VERSION ""

NS_ :

BS_:

BU_:

BO_ 256 M_Data: 8 BMS1
 SG_ Unique_ID : 16|48@1+ (1,0) [0|0] "ID"  BMS2,Cluster,TCU
 SG_ SoC : 0|16@1+ (0.1,0.0) [0.0|100.0] "%"  BMS2,Cluster,TCU

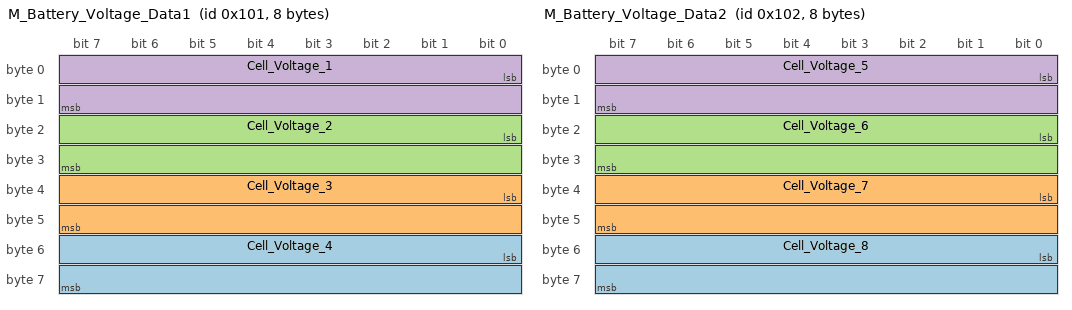
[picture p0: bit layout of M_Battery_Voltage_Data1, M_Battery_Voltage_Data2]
BO_ 257 M_Battery_Voltage_Data1: 8 BMS1
 SG_ Cell_Voltage_4 : 48|16@1+ (1,0) [0.0|5000.0] "mV"  TCU
 SG_ Cell_Voltage_3 : 32|16@1+ (1,0) [0.0|5000.0] "mV"  TCU
 SG_ Cell_Voltage_2 : 16|16@1+ (1,0) [0.0|5000.0] "mV"  TCU
 SG_ Cell_Voltage_1 : 0|16@1+ (1,0) [0.0|5000.0] "mV"  TCU

BO_ 258 M_Battery_Voltage_Data2: 8 BMS1
 SG_ Cell_Voltage_8 : 48|16@1+ (1,0) [0.0|5000.0] "mV"  TCU
 SG_ Cell_Voltage_7 : 32|16@1+ (1,0) [0.0|5000.0] "mV"  TCU
 SG_ Cell_Voltage_6 : 16|16@1+ (1,0) [0.0|5000.0] "mV"  TCU
 SG_ Cell_Voltage_5 : 0|16@1+ (1,0) [0.0|5000.0] "mV"  TCU

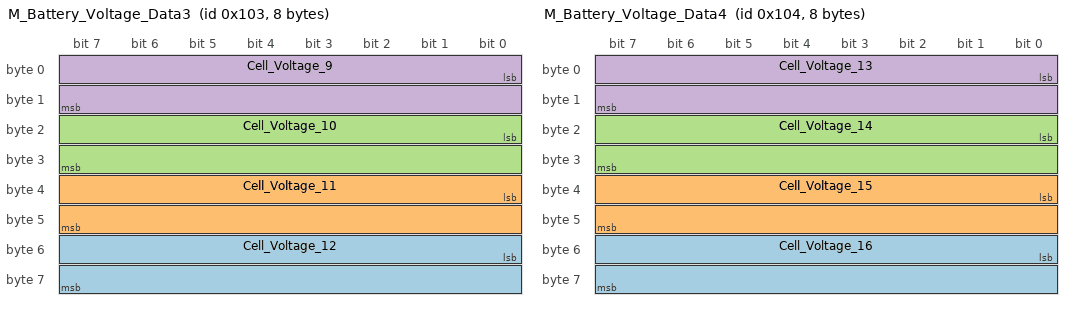
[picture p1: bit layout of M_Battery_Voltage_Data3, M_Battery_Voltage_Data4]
BO_ 259 M_Battery_Voltage_Data3: 8 BMS1
 SG_ Cell_Voltage_12 : 48|16@1+ (1,0) [0.0|5000.0] "mV"  TCU
 SG_ Cell_Voltage_11 : 32|16@1+ (1,0) [0.0|5000.0] "mV"  TCU
 SG_ Cell_Voltage_10 : 16|16@1+ (1,0) [0.0|5000.0] "mV"  TCU
 SG_ Cell_Voltage_9 : 0|16@1+ (1,0) [0.0|5000.0] "mV"  TCU

BO_ 260 M_Battery_Voltage_Data4: 8 BMS1
 SG_ Cell_Voltage_16 : 48|16@1+ (1,0) [0.0|5000.0] "mV"  TCU
 SG_ Cell_Voltage_15 : 32|16@1+ (1,0) [0.0|5000.0] "mV"  TCU
 SG_ Cell_Voltage_14 : 16|16@1+ (1,0) [0.0|5000.0] "mV"  TCU
 SG_ Cell_Voltage_13 : 0|16@1+ (1,0) [0.0|5000.0] "mV"  TCU

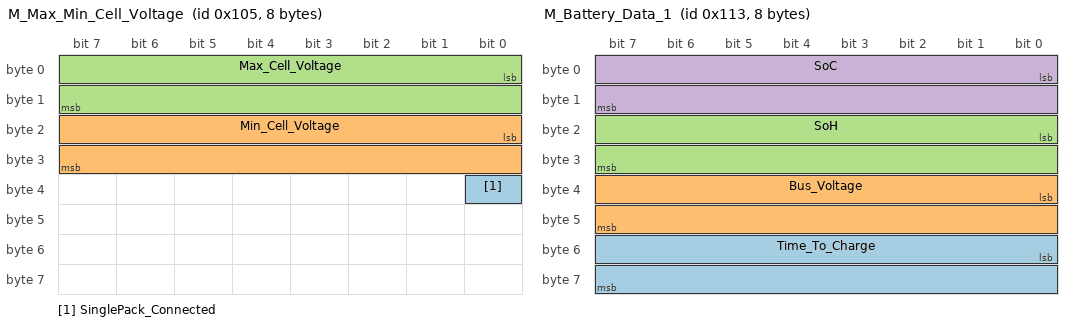
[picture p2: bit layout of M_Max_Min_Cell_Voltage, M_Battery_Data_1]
BO_ 261 M_Max_Min_Cell_Voltage: 8 BMS1
 SG_ SinglePack_Connected : 32|1@1+ (1,0) [0.0|1.0] ""  TCU
 SG_ Min_Cell_Voltage : 16|16@1+ (1,0) [0.0|5000.0] "mV"  TCU
 SG_ Max_Cell_Voltage : 0|16@1+ (1,0) [0.0|5000.0] "mV"  TCU

BO_ 262 M_Battery_PDU_Temp_Data: 8 BMS1
 SG_ PDU_Temperature_BMS : 16|16@1+ (0.01,-55.0) [-55.0|200.0] "degC"  TCU
 SG_ PDU_Temperature_AFE : 0|16@1+ (0.01,-55.0) [-55.0|200.0] "degC"  TCU

BO_ 263 M_Battery_Temp_Data_1: 8 BMS1
 SG_ Battery_Pack_Effective_Temp : 16|16@1+ (0.01,-55.0) [-55.0|200.0] "degC"  Cluster,OBC,TCU
 SG_ Balancing_Temperature_AFE : 0|16@1+ (0.01,-55.0) [-55.0|200.0] "degC"  Cluster,OBC,TCU

BO_ 264 M_Battery_Temp_Data_2: 8 BMS1
 SG_ Battery_Pack_Temp_Sensor_2 : 16|16@1+ (0.01,-55.0) [-55.0|200.0] "degC"  TCU
 SG_ Battery_Pack_Temp_Sensor_1 : 0|16@1+ (0.01,-55.0) [-55.0|200.0] "degC"  TCU

BO_ 265 M_Battery_Temp_Data_3: 8 BMS1
 SG_ Battery_Pack_Temp_Sensor_4 : 16|16@1+ (0.01,-55.0) [-55.0|200.0] "degC"  TCU
 SG_ Battery_Pack_Temp_Sensor_3 : 0|16@1+ (0.01,-55.0) [-55.0|200.0] "degC"  TCU

BO_ 272 M_BMS_Status_Data_1: 8 BMS1
 SG_ Cell16_Balancing_Status : 34|1@1+ (1,0) [0.0|1.0] ""  TCU
 SG_ Cell15_Balancing_Status : 33|1@1+ (1,0) [0.0|1.0] ""  TCU
 SG_ Cell14_Balancing_Status : 32|1@1+ (1,0) [0.0|1.0] ""  TCU
 SG_ Cell13_Balancing_Status : 31|1@1+ (1,0) [0.0|1.0] ""  TCU
 SG_ Cell12_Balancing_Status : 30|1@1+ (1,0) [0.0|1.0] ""  TCU
 SG_ Cell11_Balancing_Status : 29|1@1+ (1,0) [0.0|1.0] ""  TCU
 SG_ Cell10_Balancing_Status : 28|1@1+ (1,0) [0.0|1.0] ""  TCU
 SG_ Cell9_Balancing_Status : 27|1@1+ (1,0) [0.0|1.0] ""  TCU
 SG_ Cell8_Balancing_Status : 26|1@1+ (1,0) [0.0|1.0] ""  TCU
 SG_ Cell7_Balancing_Status : 25|1@1+ (1,0) [0.0|1.0] ""  TCU
 SG_ Cell6_Balancing_Status : 24|1@1+ (1,0) [0.0|1.0] ""  TCU
 SG_ Cell5_Balancing_Status : 23|1@1+ (1,0) [0.0|1.0] ""  TCU
 SG_ Cell4_Balancing_Status : 22|1@1+ (1,0) [0.0|1.0] ""  TCU
 SG_ Cell3_Balancing_Status : 21|1@1+ (1,0) [0.0|1.0] ""  TCU
 SG_ Cell2_Balancing_Status : 20|1@1+ (1,0) [0.0|1.0] ""  TCU
 SG_ Cell1_Balancing_Status : 19|1@1+ (1,0) [0.0|1.0] ""  TCU
 SG_ BMS_SlowChg_Status : 18|1@1+ (1,0) [0.0|1.0] ""  TCU
 SG_ BMS_SlowChg_Auth : 17|1@1+ (1,0) [0.0|1.0] ""  TCU
 SG_ BMS_Out_3_3VEnable : 16|1@1+ (1,0) [0.0|1.0] ""  TCU
 SG_ BMS_Out_Overload_Clear : 15|1@1+ (1,0) [0.0|1.0] ""  TCU
 SG_ BMS_Out_AFE_Reset : 14|1@1+ (1,0) [0.0|1.0] ""  TCU
 SG_ BMS_Out_Precharge_FET_Enable : 13|1@1+ (1,0) [0.0|1.0] ""  TCU
 SG_ BMS_Out_Discharge_FET_Enable : 12|1@1+ (1,0) [0.0|1.0] ""  TCU
 SG_ BMS_Out_Charge_FET_Enable : 11|1@1+ (1,0) [0.0|1.0] ""  TCU
 SG_ BMS_Out_Gate_Driver_Enable : 10|1@1+ (1,0) [0.0|1.0] ""  TCU
 SG_ BMS_Out_5VEnable : 9|1@1+ (1,0) [0.0|1.0] ""  TCU
 SG_ BMS_Out_9VEnable : 8|1@1+ (1,0) [0.0|1.0] ""  TCU
 SG_ BMS_Out_12VEnable : 7|1@1+ (1,0) [0.0|1.0] ""  TCU
 SG_ BMS_Out_Status : 6|1@1+ (1,0) [0.0|1.0] ""  TCU
 SG_ BMS_IN_PlugSense : 5|1@1+ (1,0) [0.0|1.0] ""  TCU
 SG_ BMS_IN_Discharge_Overcurrent : 4|1@1+ (1,0) [0.0|1.0] ""  TCU
 SG_ BMS_IN_Charge_Overcurrent : 3|1@1+ (1,0) [0.0|1.0] ""  TCU
 SG_ BMS_IN_AFE_Fault : 2|1@1+ (1,0) [0.0|1.0] ""  TCU
 SG_ BMS_IN_Supply_12V : 1|1@1+ (1,0) [0.0|1.0] ""  TCU
 SG_ BMS_IN_Supply_9V : 0|1@1+ (1,0) [0.0|1.0] ""  TCU

BO_ 273 M_Current_Limit_Data: 8 BMS1
 SG_ Regenerative_Current_Limit : 16|16@1+ (0.1,0.0) [0.0|100.0] "A"  MCU,TCU
 SG_ Discharge_Current_Limit : 0|16@1+ (0.1,-200.0) [-200.0|0.0] "A"  MCU,TCU

BO_ 274 M_Battery_Pack_V_I: 8 BMS1
 SG_ Battery_Pack_Voltage : 16|16@1+ (0.1,0.0) [0.0|100.0] "V"  MCU,TCU
 SG_ Battery_Pack_Current : 0|16@1+ (0.1,-200.0) [0.0|200.0] "A"  MCU,TCU

BO_ 275 M_Battery_Data_1: 8 BMS1
 SG_ Time_To_Charge : 48|16@1+ (1,0) [0|0] ""  Cluster,MCU,OBC,TCU
 SG_ Bus_Voltage : 32|16@1+ (0.1,0.0) [0.0|100.0] "V"  Cluster,MCU,OBC,TCU
 SG_ SoH : 16|16@1+ (0.1,0.0) [0.0|100.0] "%"  Cluster,MCU,OBC,TCU
 SG_ SoC : 0|16@1+ (0.1,0.0) [0.0|100.0] "%"  Cluster,MCU,OBC,TCU

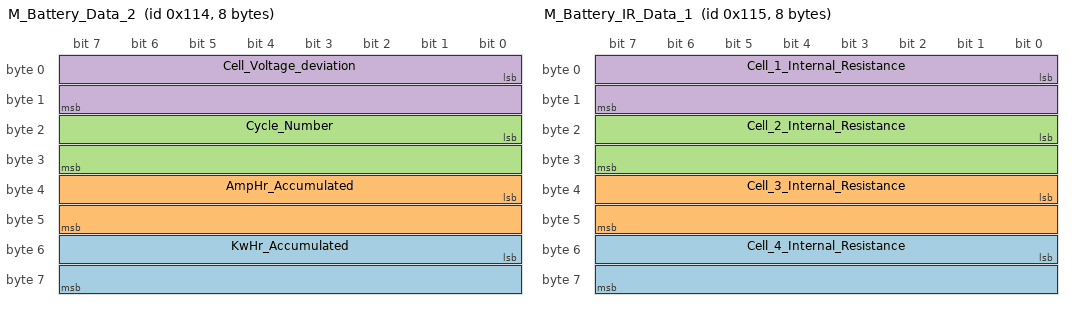
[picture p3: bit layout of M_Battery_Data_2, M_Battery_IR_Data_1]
BO_ 276 M_Battery_Data_2: 8 BMS1
 SG_ KwHr_Accumulated : 48|16@1+ (0.01,0.0) [0.0|6.0] "KwHr"  TCU
 SG_ AmpHr_Accumulated : 32|16@1+ (0.1,0.0) [0.0|100.0] "AmpHr"  TCU
 SG_ Cycle_Number : 16|16@1+ (1,0) [0.0|3000.0] "Count"  TCU
 SG_ Cell_Voltage_deviation : 0|16@1+ (1,0) [0.0|5000.0] "mV"  TCU

BO_ 277 M_Battery_IR_Data_1: 8 BMS1
 SG_ Cell_4_Internal_Resistance : 48|16@1+ (1,0) [0|0] "mOhm"  TCU
 SG_ Cell_3_Internal_Resistance : 32|16@1+ (1,0) [0|0] "mOhm"  TCU
 SG_ Cell_2_Internal_Resistance : 16|16@1+ (1,0) [0|0] "mOhm"  TCU
 SG_ Cell_1_Internal_Resistance : 0|16@1+ (1,0) [0|0] "mOhm"  TCU

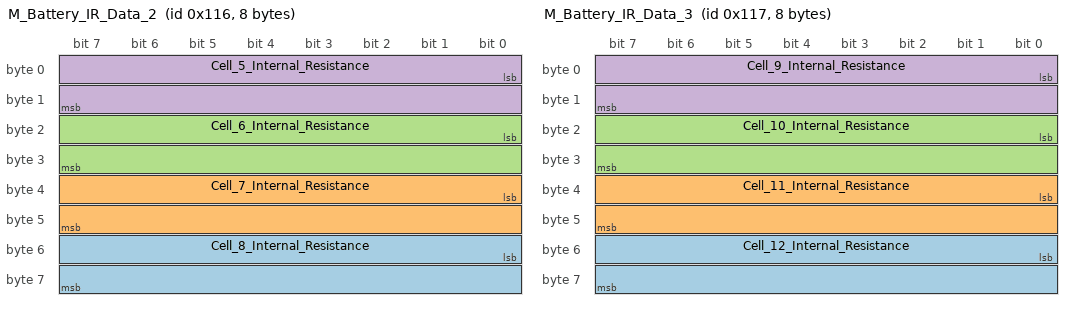
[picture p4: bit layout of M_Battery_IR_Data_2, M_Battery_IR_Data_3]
BO_ 278 M_Battery_IR_Data_2: 8 BMS1
 SG_ Cell_8_Internal_Resistance : 48|16@1+ (1,0) [0|0] "mOhm"  TCU
 SG_ Cell_7_Internal_Resistance : 32|16@1+ (1,0) [0|0] "mOhm"  TCU
 SG_ Cell_6_Internal_Resistance : 16|16@1+ (1,0) [0|0] "mOhm"  TCU
 SG_ Cell_5_Internal_Resistance : 0|16@1+ (1,0) [0|0] "mOhm"  TCU

BO_ 279 M_Battery_IR_Data_3: 8 BMS1
 SG_ Cell_12_Internal_Resistance : 48|16@1+ (1,0) [0|0] "mOhm"  TCU
 SG_ Cell_11_Internal_Resistance : 32|16@1+ (1,0) [0|0] "mOhm"  TCU
 SG_ Cell_10_Internal_Resistance : 16|16@1+ (1,0) [0|0] "mOhm"  TCU
 SG_ Cell_9_Internal_Resistance : 0|16@1+ (1,0) [0|0] "mOhm"  TCU

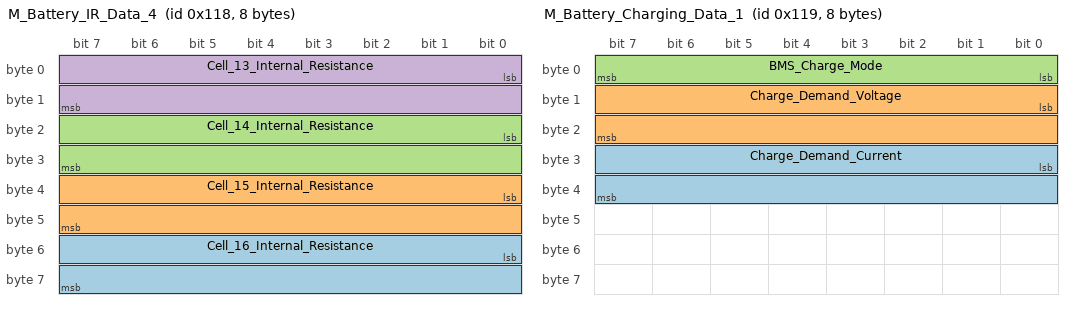
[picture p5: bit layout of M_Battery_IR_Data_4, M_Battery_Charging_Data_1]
BO_ 280 M_Battery_IR_Data_4: 8 BMS1
 SG_ Cell_16_Internal_Resistance : 48|16@1+ (1,0) [0|0] "mOhm"  TCU
 SG_ Cell_15_Internal_Resistance : 32|16@1+ (1,0) [0|0] "mOhm"  TCU
 SG_ Cell_14_Internal_Resistance : 16|16@1+ (1,0) [0|0] "mOhm"  TCU
 SG_ Cell_13_Internal_Resistance : 0|16@1+ (1,0) [0|0] "mOhm"  TCU

BO_ 281 M_Battery_Charging_Data_1: 8 BMS1
 SG_ Charge_Demand_Current : 24|16@1+ (0.1,0.0) [0|0] "mA"  OBC,TCU
 SG_ Charge_Demand_Voltage : 8|16@1+ (0.1,0.0) [0.0|100.0] "V"  OBC,TCU
 SG_ BMS_Charge_Mode : 0|8@1+ (1,0) [0.0|5.0] ""  OBC,TCU

BO_ 288 M_Battery_Data_3: 8 BMS1
 SG_ RTC_Date : 0|48@1+ (1,0) [0|0] "Sec"  TCU

BO_ 289 M_Battery_Data_4: 8 BMS1
 SG_ RTC_Time : 0|48@1+ (1,0) [0|0] ""  TCU

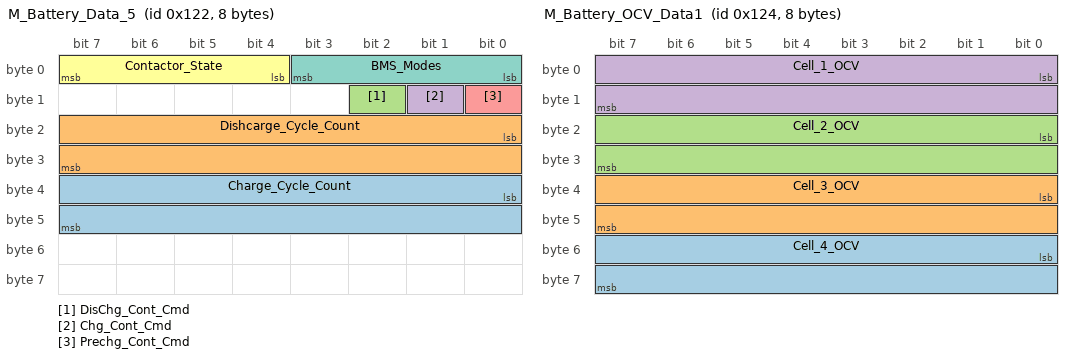
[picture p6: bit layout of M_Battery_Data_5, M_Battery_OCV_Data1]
BO_ 290 M_Battery_Data_5: 8 BMS1
 SG_ Charge_Cycle_Count : 32|16@1+ (1,0) [0.0|1000.0] "Count"  BMS2,MCU,TCU
 SG_ Dishcarge_Cycle_Count : 16|16@1+ (1,0) [0.0|1000.0] "Count"  BMS2,MCU,TCU
 SG_ DisChg_Cont_Cmd : 10|1@1+ (1,0) [0.0|1.0] ""  BMS2,MCU,TCU
 SG_ Chg_Cont_Cmd : 9|1@1+ (1,0) [0.0|1.0] ""  BMS2,MCU,TCU
 SG_ Prechg_Cont_Cmd : 8|1@1+ (1,0) [0.0|1.0] ""  BMS2,MCU,TCU
 SG_ Contactor_State : 4|4@1+ (1,0) [0.0|5.0] ""  BMS2,MCU,TCU
 SG_ BMS_Modes : 0|4@1+ (1,0) [0.0|7.0] ""  BMS2,MCU,TCU

BO_ 291 M_Battery_Fault_Data: 8 BMS1
 SG_ Ther_RunAway_Alert : 26|1@1+ (1,0) [0.0|1.0] ""  TCU
 SG_ Therm_RunAway_CutOFF : 25|1@1+ (1,0) [0.0|1.0] ""  TCU
 SG_ PDU_TempRise_Perm : 24|1@1+ (1,0) [0.0|1.0] ""  TCU
 SG_ Batt_TempRise_Perm : 23|1@1+ (1,0) [0.0|1.0] ""  TCU
 SG_ Dis_CutOff : 22|1@1+ (1,0) [0.0|1.0] ""  TCU
 SG_ Charge_CutOff : 21|1@1+ (1,0) [0.0|1.0] ""  TCU
 SG_ Dis_OvrTemp_Err : 20|1@1+ (1,0) [0.0|1.0] ""  TCU
 SG_ Dis_OvrTemp_Warn : 19|1@1+ (1,0) [0.0|1.0] ""  TCU
 SG_ Chg_OvrTemp_Warn : 18|1@1+ (1,0) [0.0|1.0] ""  TCU
 SG_ Chg_Und_Vol_Warn : 17|1@1+ (1,0) [0.0|1.0] ""  TCU
 SG_ Chg_Ovr_Vol_Perm : 16|1@1+ (1,0) [0.0|1.0] ""  TCU
 SG_ Chg_Ovr_Vol_Err : 15|1@1+ (1,0) [0.0|1.0] ""  TCU
 SG_ Chg_Ovr_Vol_Warn : 14|1@1+ (1,0) [0.0|1.0] ""  TCU
 SG_ PDU_Temp_Err : 13|1@1+ (1,0) [0.0|1.0] ""  TCU
 SG_ Over_Temp_Perm : 12|1@1+ (1,0) [0.0|1.0] ""  TCU
 SG_ Short_Circuit_Perm : 11|1@1+ (1,0) [0.0|1.0] ""  TCU
 SG_ Short_Circuit_Err : 10|1@1+ (1,0) [0.0|1.0] ""  TCU
 SG_ Cell_Und_Voltage_Perm : 9|1@1+ (1,0) [0.0|1.0] ""  TCU
 SG_ Cell_Ovr_Voltage_Perm : 8|1@1+ (1,0) [0.0|1.0] ""  TCU
 SG_ Cell_Und_Voltage_Err : 7|1@1+ (1,0) [0.0|1.0] ""  TCU
 SG_ Cell_Ovr_Voltage_Err : 6|1@1+ (1,0) [0.0|1.0] ""  TCU
 SG_ Dis_Connection_Err : 5|1@1+ (1,0) [0.0|1.0] ""  TCU
 SG_ Main_Connection_Err : 4|1@1+ (1,0) [0.0|1.0] ""  TCU
 SG_ Precharge_Fail_Perm : 3|1@1+ (1,0) [0.0|1.0] ""  TCU
 SG_ Precharge_Fail : 2|1@1+ (1,0) [0.0|1.0] ""  TCU
 SG_ PreCharge_Err_Short : 1|1@1+ (1,0) [0.0|1.0] ""  TCU
 SG_ BMS_CutOff : 0|1@1+ (1,0) [0.0|1.0] ""  TCU

BO_ 292 M_Battery_OCV_Data1: 8 BMS1
 SG_ Cell_4_OCV : 48|16@1+ (1,0) [0.0|5000.0] "mV"  TCU
 SG_ Cell_3_OCV : 32|16@1+ (1,0) [0.0|5000.0] "mV"  TCU
 SG_ Cell_2_OCV : 16|16@1+ (1,0) [0.0|5000.0] "mV"  TCU
 SG_ Cell_1_OCV : 0|16@1+ (1,0) [0.0|5000.0] "mV"  TCU

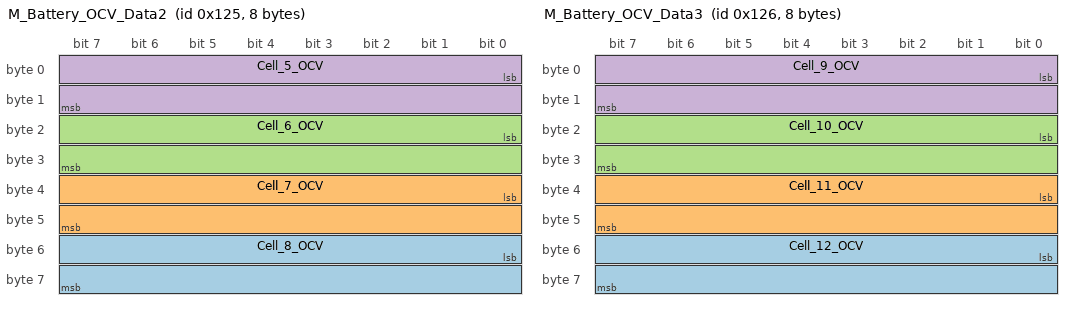
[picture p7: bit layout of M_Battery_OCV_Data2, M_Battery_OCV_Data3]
BO_ 293 M_Battery_OCV_Data2: 8 BMS1
 SG_ Cell_8_OCV : 48|16@1+ (1,0) [0.0|5000.0] "mV"  TCU
 SG_ Cell_7_OCV : 32|16@1+ (1,0) [0.0|5000.0] "mV"  TCU
 SG_ Cell_6_OCV : 16|16@1+ (1,0) [0.0|5000.0] "mV"  TCU
 SG_ Cell_5_OCV : 0|16@1+ (1,0) [0.0|5000.0] "mV"  TCU

BO_ 294 M_Battery_OCV_Data3: 8 BMS1
 SG_ Cell_12_OCV : 48|16@1+ (1,0) [0.0|5000.0] "mV"  TCU
 SG_ Cell_11_OCV : 32|16@1+ (1,0) [0.0|5000.0] "mV"  TCU
 SG_ Cell_10_OCV : 16|16@1+ (1,0) [0.0|5000.0] "mV"  TCU
 SG_ Cell_9_OCV : 0|16@1+ (1,0) [0.0|5000.0] "mV"  TCU

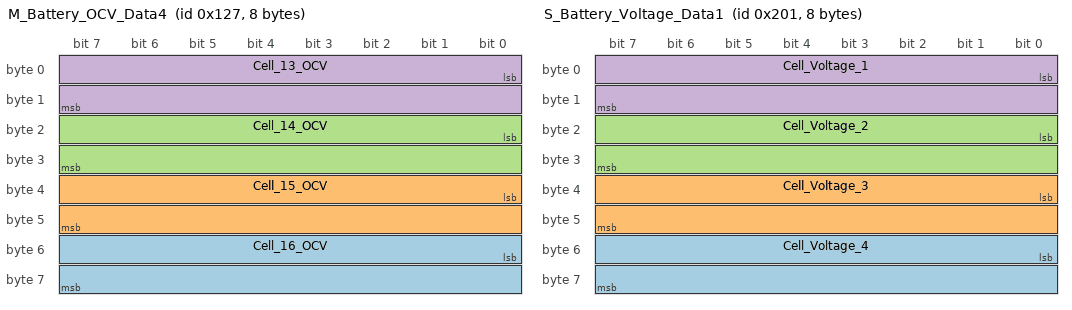
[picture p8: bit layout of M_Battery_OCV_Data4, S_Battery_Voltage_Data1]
BO_ 295 M_Battery_OCV_Data4: 8 BMS1
 SG_ Cell_16_OCV : 48|16@1+ (1,0) [0.0|5000.0] "mV"  TCU
 SG_ Cell_15_OCV : 32|16@1+ (1,0) [0.0|5000.0] "mV"  TCU
 SG_ Cell_14_OCV : 16|16@1+ (1,0) [0.0|5000.0] "mV"  TCU
 SG_ Cell_13_OCV : 0|16@1+ (1,0) [0.0|5000.0] "mV"  TCU

BO_ 512 S_Data: 8 BMS2
 SG_ Unique_ID : 16|48@1+ (1,0) [0|0] "ID"  BMS1,Cluster,TCU
 SG_ SoC : 0|16@1+ (0.1,0.0) [0.0|100.0] "%"  BMS1,Cluster,TCU

BO_ 513 S_Battery_Voltage_Data1: 8 BMS2
 SG_ Cell_Voltage_4 : 48|16@1+ (1,0) [0.0|5000.0] "mV"  TCU
 SG_ Cell_Voltage_3 : 32|16@1+ (1,0) [0.0|5000.0] "mV"  TCU
 SG_ Cell_Voltage_2 : 16|16@1+ (1,0) [0.0|5000.0] "mV"  TCU
 SG_ Cell_Voltage_1 : 0|16@1+ (1,0) [0.0|5000.0] "mV"  TCU

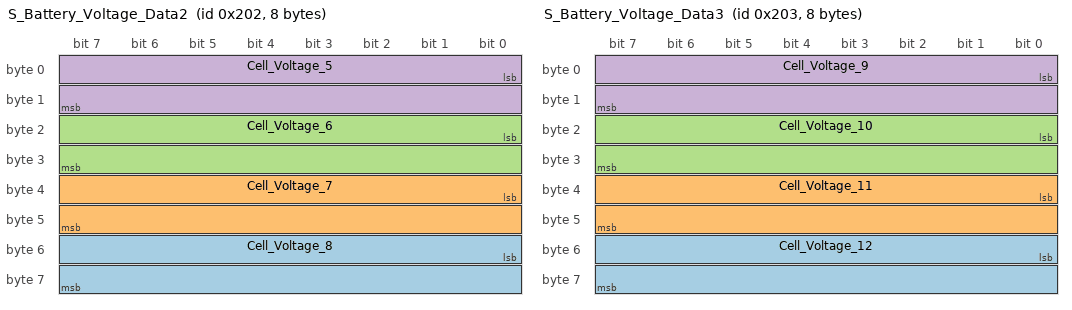
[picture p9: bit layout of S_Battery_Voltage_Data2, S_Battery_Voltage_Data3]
BO_ 514 S_Battery_Voltage_Data2: 8 BMS2
 SG_ Cell_Voltage_8 : 48|16@1+ (1,0) [0.0|5000.0] "mV"  TCU
 SG_ Cell_Voltage_7 : 32|16@1+ (1,0) [0.0|5000.0] "mV"  TCU
 SG_ Cell_Voltage_6 : 16|16@1+ (1,0) [0.0|5000.0] "mV"  TCU
 SG_ Cell_Voltage_5 : 0|16@1+ (1,0) [0.0|5000.0] "mV"  TCU

BO_ 515 S_Battery_Voltage_Data3: 8 BMS2
 SG_ Cell_Voltage_12 : 48|16@1+ (1,0) [0.0|5000.0] "mV"  TCU
 SG_ Cell_Voltage_11 : 32|16@1+ (1,0) [0.0|5000.0] "mV"  TCU
 SG_ Cell_Voltage_10 : 16|16@1+ (1,0) [0.0|5000.0] "mV"  TCU
 SG_ Cell_Voltage_9 : 0|16@1+ (1,0) [0.0|5000.0] "mV"  TCU

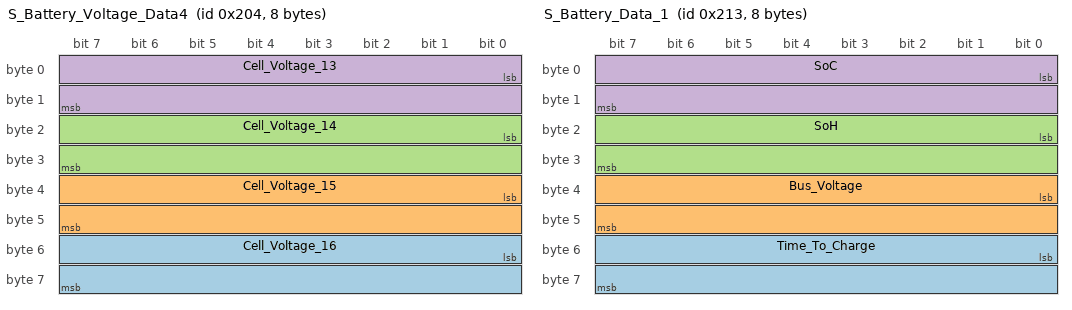
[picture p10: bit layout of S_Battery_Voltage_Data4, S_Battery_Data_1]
BO_ 516 S_Battery_Voltage_Data4: 8 BMS2
 SG_ Cell_Voltage_16 : 48|16@1+ (1,0) [0.0|5000.0] "mV"  TCU
 SG_ Cell_Voltage_15 : 32|16@1+ (1,0) [0.0|5000.0] "mV"  TCU
 SG_ Cell_Voltage_14 : 16|16@1+ (1,0) [0.0|5000.0] "mV"  TCU
 SG_ Cell_Voltage_13 : 0|16@1+ (1,0) [0.0|5000.0] "mV"  TCU

BO_ 517 S_Max_Min_Cell_Voltage: 8 BMS2
 SG_ Min_Cell_Voltage : 16|16@1+ (1,0) [0.0|5000.0] "mV"  TCU
 SG_ Max_Cell_Voltage : 0|16@1+ (1,0) [0.0|5000.0] "mV"  TCU

BO_ 518 S_Battery_PDU_Temp_Data: 8 BMS2
 SG_ PDU_Temperature_BMS : 16|16@1+ (0.01,-55.0) [-55.0|200.0] "degC"  OBC,TCU
 SG_ PDU_Temperature_AFE : 0|16@1+ (0.01,-55.0) [-55.0|200.0] "degC"  OBC,TCU

BO_ 519 S_Battery_Temp_Data_1: 8 BMS2
 SG_ Battery_Pack_Effective_Temp : 16|16@1+ (0.01,-55.0) [-55.0|200.0] "degC"  OBC,TCU
 SG_ Balancing_Temperature_AFE : 0|16@1+ (0.01,-55.0) [-55.0|200.0] "degC"  OBC,TCU

BO_ 520 S_Battery_Temp_Data_2: 8 BMS2
 SG_ Battery_Pack_Temp_Sensor_2 : 16|16@1+ (0.01,-55.0) [-55.0|200.0] "degC"  OBC,TCU
 SG_ Battery_Pack_Temp_Sensor_1 : 0|16@1+ (0.01,-55.0) [-55.0|200.0] "degC"  OBC,TCU

BO_ 521 S_Battery_Temp_Data_3: 8 BMS2
 SG_ Battery_Pack_Temp_Sensor_4 : 16|16@1+ (0.01,-55.0) [-55.0|200.0] "degC"  OBC,TCU
 SG_ Battery_Pack_Temp_Sensor_3 : 0|16@1+ (0.01,-55.0) [-55.0|200.0] "degC"  OBC,TCU

BO_ 528 S_BMS_Status_Data_1: 8 BMS2
 SG_ Cell16_Balancing_Status : 34|1@1+ (1,0) [0.0|1.0] ""  TCU
 SG_ Cell15_Balancing_Status : 33|1@1+ (1,0) [0.0|1.0] ""  TCU
 SG_ Cell14_Balancing_Status : 32|1@1+ (1,0) [0.0|1.0] ""  TCU
 SG_ Cell13_Balancing_Status : 31|1@1+ (1,0) [0.0|1.0] ""  TCU
 SG_ Cell12_Balancing_Status : 30|1@1+ (1,0) [0.0|1.0] ""  TCU
 SG_ Cell11_Balancing_Status : 29|1@1+ (1,0) [0.0|1.0] ""  TCU
 SG_ Cell10_Balancing_Status : 28|1@1+ (1,0) [0.0|1.0] ""  TCU
 SG_ Cell9_Balancing_Status : 27|1@1+ (1,0) [0.0|1.0] ""  TCU
 SG_ Cell8_Balancing_Status : 26|1@1+ (1,0) [0.0|1.0] ""  TCU
 SG_ Cell7_Balancing_Status : 25|1@1+ (1,0) [0.0|1.0] ""  TCU
 SG_ Cell6_Balancing_Status : 24|1@1+ (1,0) [0.0|1.0] ""  TCU
 SG_ Cell5_Balancing_Status : 23|1@1+ (1,0) [0.0|1.0] ""  TCU
 SG_ Cell4_Balancing_Status : 22|1@1+ (1,0) [0.0|1.0] ""  TCU
 SG_ Cell3_Balancing_Status : 21|1@1+ (1,0) [0.0|1.0] ""  TCU
 SG_ Cell2_Balancing_Status : 20|1@1+ (1,0) [0.0|1.0] ""  TCU
 SG_ Cell1_Balancing_Status : 19|1@1+ (1,0) [0.0|1.0] ""  TCU
 SG_ BMS_SlowChg_Status : 18|1@1+ (1,0) [0.0|1.0] ""  TCU
 SG_ BMS_SlowChg_Auth : 17|1@1+ (1,0) [0.0|1.0] ""  TCU
 SG_ BMS_Out_3_3VEnable : 16|1@1+ (1,0) [0.0|1.0] ""  TCU
 SG_ BMS_Out_Overload_Clear : 15|1@1+ (1,0) [0.0|1.0] ""  TCU
 SG_ BMS_Out_AFE_Reset : 14|1@1+ (1,0) [0.0|1.0] ""  TCU
 SG_ BMS_Out_Precharge_FET_Enable : 13|1@1+ (1,0) [0.0|1.0] ""  TCU
 SG_ BMS_Out_Discharge_FET_Enable : 12|1@1+ (1,0) [0.0|1.0] ""  TCU
 SG_ BMS_Out_Charge_FET_Enable : 11|1@1+ (1,0) [0.0|1.0] ""  TCU
 SG_ BMS_Out_Gate_Driver_Enable : 10|1@1+ (1,0) [0.0|1.0] ""  TCU
 SG_ BMS_Out_5VEnable : 9|1@1+ (1,0) [0.0|1.0] ""  TCU
 SG_ BMS_Out_9VEnable : 8|1@1+ (1,0) [0.0|1.0] ""  TCU
 SG_ BMS_Out_12VEnable : 7|1@1+ (1,0) [0.0|1.0] ""  TCU
 SG_ BMS_Out_Status : 6|1@1+ (1,0) [0.0|1.0] ""  TCU
 SG_ BMS_IN_PlugSense : 5|1@1+ (1,0) [0.0|1.0] ""  TCU
 SG_ BMS_IN_Discharge_Overcurrent : 4|1@1+ (1,0) [0.0|1.0] ""  TCU
 SG_ BMS_IN_Charge_Overcurrent : 3|1@1+ (1,0) [0.0|1.0] ""  TCU
 SG_ BMS_IN_AFE_Fault : 2|1@1+ (1,0) [0.0|1.0] ""  TCU
 SG_ BMS_IN_Supply_12V : 1|1@1+ (1,0) [0.0|1.0] ""  TCU
 SG_ BMS_IN_Supply_9V : 0|1@1+ (1,0) [0.0|1.0] ""  TCU

BO_ 529 S_Current_Limit_Data: 8 BMS2
 SG_ Regenerative_Current_Limit : 16|16@1+ (1,0) [-200.0|600.0] "A"  MCU,TCU
 SG_ Discharge_Current_Limit : 0|16@1+ (1,0) [-200.0|200.0] "A"  MCU,TCU

BO_ 530 S_Battery_Pack_V_I: 8 BMS2
 SG_ Battery_Pack_Voltage : 16|16@1+ (0.1,0.0) [0.0|100.0] "V"  MCU,TCU
 SG_ Battery_Pack_Current : 0|16@1+ (0.1,0.0) [0.0|200.0] "A"  MCU,TCU

BO_ 531 S_Battery_Data_1: 8 BMS2
 SG_ Time_To_Charge : 48|16@1+ (1,0) [0|0] ""  MCU,OBC,TCU
 SG_ Bus_Voltage : 32|16@1+ (0.1,0.0) [0.0|100.0] "V"  MCU,OBC,TCU
 SG_ SoH : 16|16@1+ (0.1,0.0) [0.0|100.0] "%"  MCU,OBC,TCU
 SG_ SoC : 0|16@1+ (0.1,0.0) [0.0|100.0] "%"  MCU,OBC,TCU

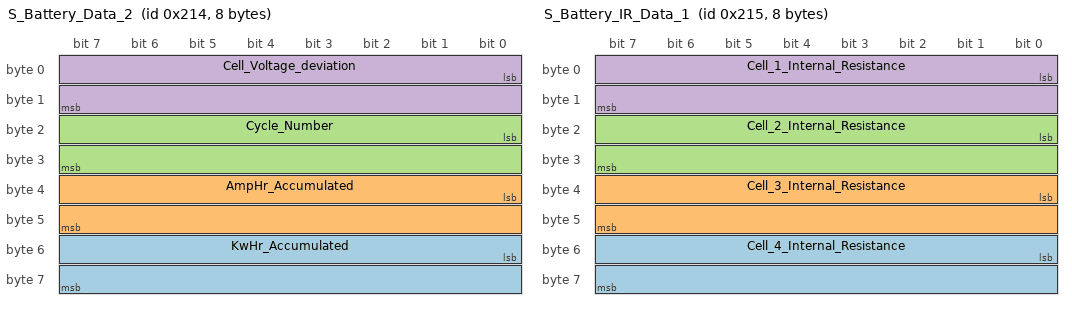
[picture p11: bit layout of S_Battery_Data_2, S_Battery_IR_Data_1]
BO_ 532 S_Battery_Data_2: 8 BMS2
 SG_ KwHr_Accumulated : 48|16@1+ (0.01,0.0) [0.0|6.0] "KwHr"  TCU
 SG_ AmpHr_Accumulated : 32|16@1+ (0.1,0.0) [0.0|100.0] "AmpHr"  TCU
 SG_ Cycle_Number : 16|16@1+ (1,0) [0.0|3000.0] "Count"  TCU
 SG_ Cell_Voltage_deviation : 0|16@1+ (1,0) [0.0|5000.0] "mV"  TCU

BO_ 533 S_Battery_IR_Data_1: 8 BMS2
 SG_ Cell_4_Internal_Resistance : 48|16@1+ (1,0) [0|0] "mOhm"  TCU
 SG_ Cell_3_Internal_Resistance : 32|16@1+ (1,0) [0|0] "mOhm"  TCU
 SG_ Cell_2_Internal_Resistance : 16|16@1+ (1,0) [0|0] "mOhm"  TCU
 SG_ Cell_1_Internal_Resistance : 0|16@1+ (1,0) [0|0] "mOhm"  TCU

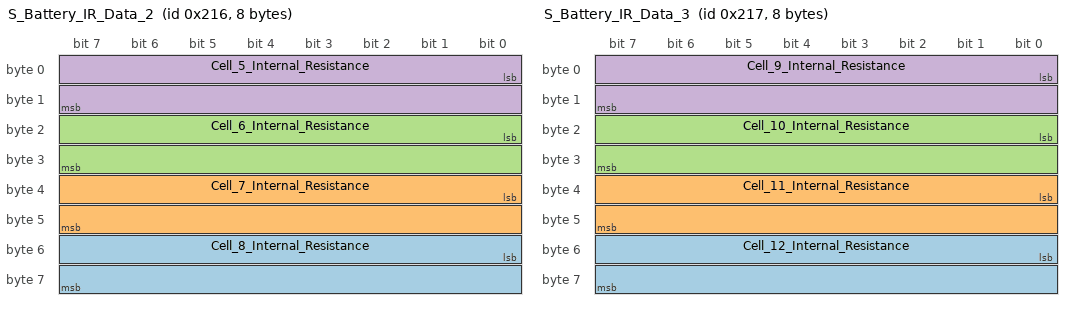
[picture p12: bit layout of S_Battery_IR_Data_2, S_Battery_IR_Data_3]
BO_ 534 S_Battery_IR_Data_2: 8 BMS2
 SG_ Cell_8_Internal_Resistance : 48|16@1+ (1,0) [0|0] "mOhm"  TCU
 SG_ Cell_7_Internal_Resistance : 32|16@1+ (1,0) [0|0] "mOhm"  TCU
 SG_ Cell_6_Internal_Resistance : 16|16@1+ (1,0) [0|0] "mOhm"  TCU
 SG_ Cell_5_Internal_Resistance : 0|16@1+ (1,0) [0|0] "mOhm"  TCU

BO_ 535 S_Battery_IR_Data_3: 8 BMS2
 SG_ Cell_12_Internal_Resistance : 48|16@1+ (1,0) [0|0] "mOhm"  TCU
 SG_ Cell_11_Internal_Resistance : 32|16@1+ (1,0) [0|0] "mOhm"  TCU
 SG_ Cell_10_Internal_Resistance : 16|16@1+ (1,0) [0|0] "mOhm"  TCU
 SG_ Cell_9_Internal_Resistance : 0|16@1+ (1,0) [0|0] "mOhm"  TCU

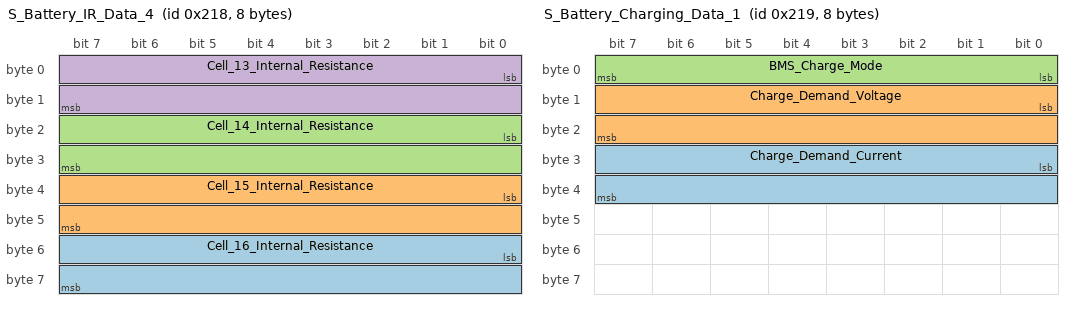
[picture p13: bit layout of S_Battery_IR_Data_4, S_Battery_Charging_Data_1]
BO_ 536 S_Battery_IR_Data_4: 8 BMS2
 SG_ Cell_16_Internal_Resistance : 48|16@1+ (1,0) [0|0] "mOhm"  TCU
 SG_ Cell_15_Internal_Resistance : 32|16@1+ (1,0) [0|0] "mOhm"  TCU
 SG_ Cell_14_Internal_Resistance : 16|16@1+ (1,0) [0|0] "mOhm"  TCU
 SG_ Cell_13_Internal_Resistance : 0|16@1+ (1,0) [0|0] "mOhm"  TCU

BO_ 537 S_Battery_Charging_Data_1: 8 BMS2
 SG_ Charge_Demand_Current : 24|16@1+ (0.1,0.0) [0|0] "mA"  OBC,TCU
 SG_ Charge_Demand_Voltage : 8|16@1+ (0.1,0.0) [0.0|100.0] "V"  OBC,TCU
 SG_ BMS_Charge_Mode : 0|8@1+ (1,0) [0.0|5.0] ""  OBC,TCU

BO_ 544 S_Battery_Data_3: 8 BMS2
 SG_ RTC_Date : 0|48@1+ (1,0) [0|0] "Sec"  TCU

BO_ 545 S_Battery_Data_4: 8 BMS2
 SG_ RTC_Time : 0|48@1+ (1,0) [0|0] ""  TCU

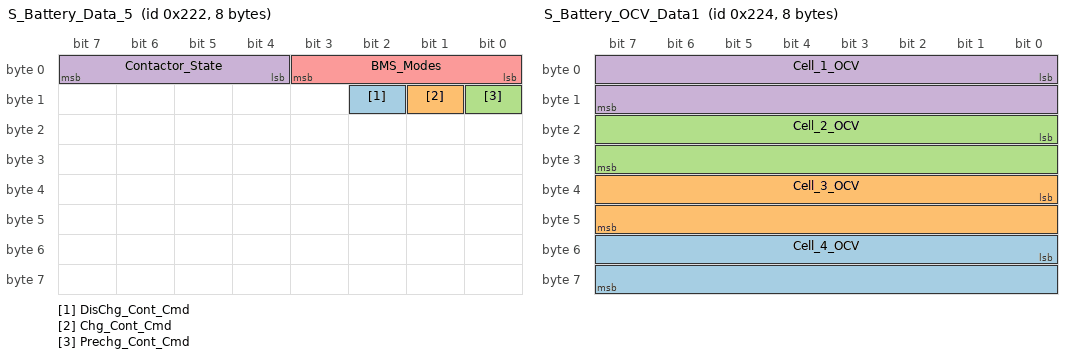
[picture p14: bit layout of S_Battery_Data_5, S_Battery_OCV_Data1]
BO_ 546 S_Battery_Data_5: 8 BMS2
 SG_ DisChg_Cont_Cmd : 10|1@1+ (1,0) [0.0|1.0] ""  BMS1,MCU,TCU
 SG_ Chg_Cont_Cmd : 9|1@1+ (1,0) [0.0|1.0] ""  BMS1,MCU,TCU
 SG_ Prechg_Cont_Cmd : 8|1@1+ (1,0) [0.0|1.0] ""  BMS1,MCU,TCU
 SG_ Contactor_State : 4|4@1+ (1,0) [0.0|5.0] ""  BMS1,MCU,TCU
 SG_ BMS_Modes : 0|4@1+ (1,0) [0.0|7.0] ""  BMS1,MCU,TCU

BO_ 547 S_Battery_Fault_Data: 8 BMS2
 SG_ Ther_RunAway_Alert : 26|1@1+ (1,0) [0.0|1.0] ""  TCU
 SG_ Therm_RunAway_CutOFF : 25|1@1+ (1,0) [0.0|1.0] ""  TCU
 SG_ PDU_TempRise_Perm : 24|1@1+ (1,0) [0.0|1.0] ""  TCU
 SG_ Batt_TempRise_Perm : 23|1@1+ (1,0) [0.0|1.0] ""  TCU
 SG_ Dis_CutOff : 22|1@1+ (1,0) [0.0|1.0] ""  TCU
 SG_ Charge_CutOff : 21|1@1+ (1,0) [0.0|1.0] ""  TCU
 SG_ Dis_OvrTemp_Err : 20|1@1+ (1,0) [0.0|1.0] ""  TCU
 SG_ Dis_OvrTemp_Warn : 19|1@1+ (1,0) [0.0|1.0] ""  TCU
 SG_ Chg_OvrTemp_Warn : 18|1@1+ (1,0) [0.0|1.0] ""  TCU
 SG_ Chg_Und_Vol_Warn : 17|1@1+ (1,0) [0.0|1.0] ""  TCU
 SG_ Chg_Ovr_Vol_Perm : 16|1@1+ (1,0) [0.0|1.0] ""  TCU
 SG_ Chg_Ovr_Vol_Err : 15|1@1+ (1,0) [0.0|1.0] ""  TCU
 SG_ Chg_Ovr_Vol_Warn : 14|1@1+ (1,0) [0.0|1.0] ""  TCU
 SG_ PDU_Temp_Err : 13|1@1+ (1,0) [0.0|1.0] ""  TCU
 SG_ Over_Temp_Perm : 12|1@1+ (1,0) [0.0|1.0] ""  TCU
 SG_ Short_Circuit_Perm : 11|1@1+ (1,0) [0.0|1.0] ""  TCU
 SG_ Short_Circuit_Err : 10|1@1+ (1,0) [0.0|1.0] ""  TCU
 SG_ Cell_Und_Voltage_Perm : 9|1@1+ (1,0) [0.0|1.0] ""  TCU
 SG_ Cell_Ovr_Voltage_Perm : 8|1@1+ (1,0) [0.0|1.0] ""  TCU
 SG_ Cell_Und_Voltage : 7|1@1+ (1,0) [0.0|1.0] ""  TCU
 SG_ Cell_Ovr_Voltage : 6|1@1+ (1,0) [0.0|1.0] ""  TCU
 SG_ Dis_Connection_Err : 5|1@1+ (1,0) [0.0|1.0] ""  TCU
 SG_ Main_Connection_Err : 4|1@1+ (1,0) [0.0|1.0] ""  TCU
 SG_ Precharge_Fail_Perm : 3|1@1+ (1,0) [0.0|1.0] ""  TCU
 SG_ Precharge_Fail : 2|1@1+ (1,0) [0.0|1.0] ""  TCU
 SG_ PreCharge_Err_Short : 1|1@1+ (1,0) [0.0|1.0] ""  TCU
 SG_ BMS_CutOff : 0|1@1+ (1,0) [0.0|1.0] ""  TCU

BO_ 548 S_Battery_OCV_Data1: 8 BMS2
 SG_ Cell_4_OCV : 48|16@1+ (1,0) [0.0|5000.0] "mV"  TCU
 SG_ Cell_3_OCV : 32|16@1+ (1,0) [0.0|5000.0] "mV"  TCU
 SG_ Cell_2_OCV : 16|16@1+ (1,0) [0.0|5000.0] "mV"  TCU
 SG_ Cell_1_OCV : 0|16@1+ (1,0) [0.0|5000.0] "mV"  TCU

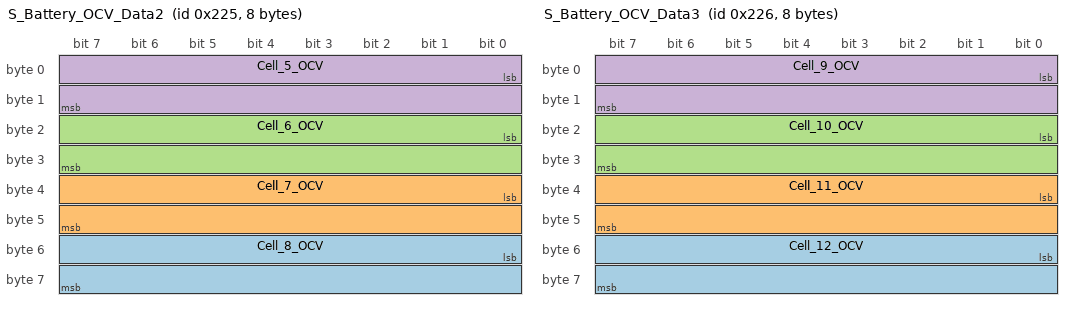
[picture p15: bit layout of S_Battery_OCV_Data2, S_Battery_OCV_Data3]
BO_ 549 S_Battery_OCV_Data2: 8 BMS2
 SG_ Cell_8_OCV : 48|16@1+ (1,0) [0.0|5000.0] "mV"  TCU
 SG_ Cell_7_OCV : 32|16@1+ (1,0) [0.0|5000.0] "mV"  TCU
 SG_ Cell_6_OCV : 16|16@1+ (1,0) [0.0|5000.0] "mV"  TCU
 SG_ Cell_5_OCV : 0|16@1+ (1,0) [0.0|5000.0] "mV"  TCU

BO_ 550 S_Battery_OCV_Data3: 8 BMS2
 SG_ Cell_12_OCV : 48|16@1+ (1,0) [0.0|5000.0] "mV"  TCU
 SG_ Cell_11_OCV : 32|16@1+ (1,0) [0.0|5000.0] "mV"  TCU
 SG_ Cell_10_OCV : 16|16@1+ (1,0) [0.0|5000.0] "mV"  TCU
 SG_ Cell_9_OCV : 0|16@1+ (1,0) [0.0|5000.0] "mV"  TCU

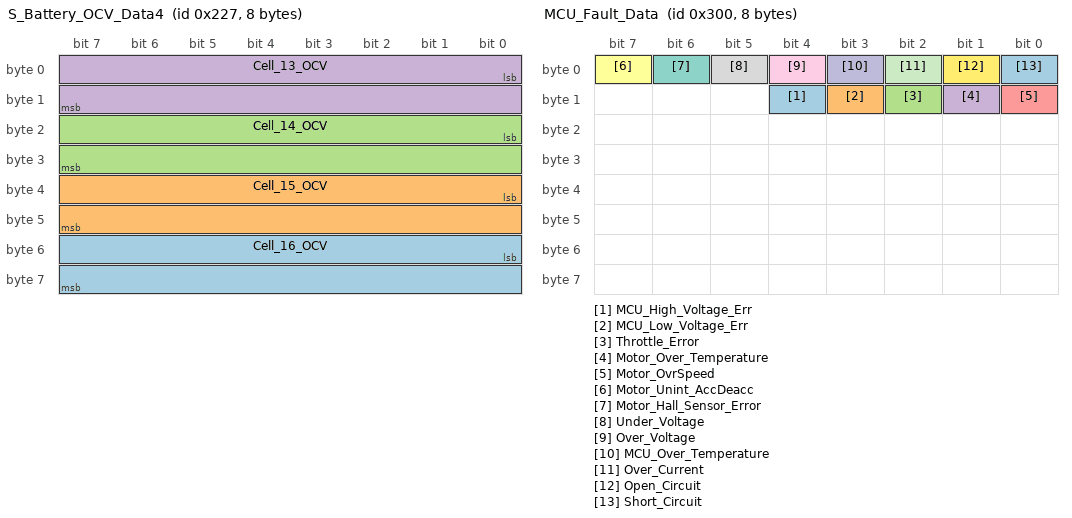
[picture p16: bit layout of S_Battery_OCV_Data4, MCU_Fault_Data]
BO_ 551 S_Battery_OCV_Data4: 8 BMS2
 SG_ Cell_16_OCV : 48|16@1+ (1,0) [0.0|5000.0] "mV"  TCU
 SG_ Cell_15_OCV : 32|16@1+ (1,0) [0.0|5000.0] "mV"  TCU
 SG_ Cell_14_OCV : 16|16@1+ (1,0) [0.0|5000.0] "mV"  TCU
 SG_ Cell_13_OCV : 0|16@1+ (1,0) [0.0|5000.0] "mV"  TCU

BO_ 768 MCU_Fault_Data: 8 MCU
 SG_ MCU_High_Voltage_Err : 12|1@1+ (1,0) [0.0|1.0] ""  BMS1,BMS2,Cluster,TCU
 SG_ MCU_Low_Voltage_Err : 11|1@1+ (1,0) [0.0|1.0] ""  BMS1,BMS2,Cluster,TCU
 SG_ Throttle_Error : 10|1@1+ (1,0) [0.0|1.0] ""  BMS1,BMS2,Cluster,TCU
 SG_ Motor_Over_Temperature : 9|1@1+ (1,0) [0.0|1.0] ""  BMS1,BMS2,Cluster,TCU
 SG_ Motor_OvrSpeed : 8|1@1+ (1,0) [0.0|1.0] ""  BMS1,BMS2,Cluster,TCU
 SG_ Motor_Unint_AccDeacc : 7|1@1+ (1,0) [0.0|1.0] ""  BMS1,BMS2,Cluster,TCU
 SG_ Motor_Hall_Sensor_Error : 6|1@1+ (1,0) [0.0|1.0] ""  BMS1,BMS2,Cluster,TCU
 SG_ Under_Voltage : 5|1@1+ (1,0) [0.0|1.0] ""  BMS1,BMS2,Cluster,TCU
 SG_ Over_Voltage : 4|1@1+ (1,0) [0.0|1.0] ""  BMS1,BMS2,Cluster,TCU
 SG_ MCU_Over_Temperature : 3|1@1+ (1,0) [0.0|1.0] ""  BMS1,BMS2,Cluster,TCU
 SG_ Over_Current : 2|1@1+ (1,0) [0.0|1.0] ""  BMS1,BMS2,Cluster,TCU
 SG_ Open_Circuit : 1|1@1+ (1,0) [0.0|1.0] ""  BMS1,BMS2,Cluster,TCU
 SG_ Short_Circuit : 0|1@1+ (1,0) [0.0|1.0] ""  BMS1,BMS2,Cluster,TCU

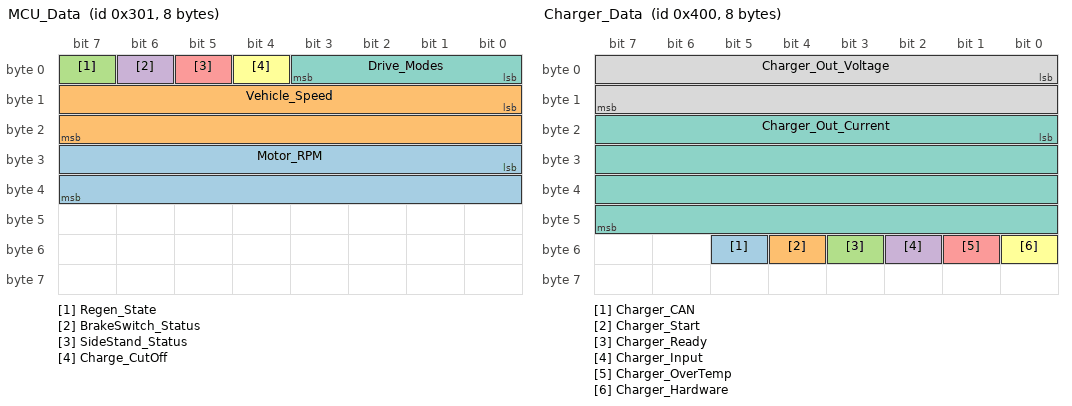
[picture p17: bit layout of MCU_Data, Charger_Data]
BO_ 769 MCU_Data: 8 MCU
 SG_ Motor_RPM : 24|16@1+ (1,0) [0.0|4000.0] "RPM"  BMS1,BMS2,Cluster,TCU
 SG_ Vehicle_Speed : 8|16@1+ (1,0) [0.0|200.0] "km/h"  BMS1,BMS2,Cluster,TCU
 SG_ Regen_State : 7|1@1+ (1,0) [0.0|1.0] ""  BMS1,BMS2,Cluster,TCU
 SG_ BrakeSwitch_Status : 6|1@1+ (1,0) [0.0|1.0] ""  BMS1,BMS2,Cluster,TCU
 SG_ SideStand_Status : 5|1@1+ (1,0) [0.0|1.0] ""  BMS1,BMS2,Cluster,TCU
 SG_ Charge_CutOff : 4|1@1+ (1,0) [0.0|1.0] ""  BMS1,BMS2,Cluster,TCU
 SG_ Drive_Modes : 0|4@1+ (1,0) [0.0|5.0] ""  BMS1,BMS2,Cluster,TCU

BO_ 770 MCU_Odo_Data: 8 MCU
 SG_ Trip_Odo_Data : 32|32@1+ (0.1,0.0) [0.0|4925672.0] "Meters"  Cluster,TCU
 SG_ Vehicle_Odo_Data : 0|32@1+ (0.1,0.0) [0.0|4925672.0] "Meters"  Cluster,TCU

BO_ 771 MCU_Temp_Data: 8 MCU
 SG_ Motor_Temp_Data : 16|16@1- (0.1,0.0) [0.0|4925672.0] "degC"  Cluster,TCU
 SG_ Controller_Temp_Data : 0|16@1- (0.1,0.0) [0.0|4925672.0] "degC"  Cluster,TCU

BO_ 1024 Charger_Data: 8 OBC
 SG_ Charger_CAN : 53|1@1+ (1,0) [0.0|1.0] ""  BMS1,BMS2,TCU
 SG_ Charger_Start : 52|1@1+ (1,0) [0.0|1.0] ""  BMS1,BMS2,TCU
 SG_ Charger_Ready : 51|1@1+ (1,0) [0.0|1.0] ""  BMS1,BMS2,TCU
 SG_ Charger_Input : 50|1@1+ (1,0) [0.0|1.0] ""  BMS1,BMS2,TCU
 SG_ Charger_OverTemp : 49|1@1+ (1,0) [0.0|1.0] ""  BMS1,BMS2,TCU
 SG_ Charger_Hardware : 48|1@1+ (1,0) [0.0|1.0] ""  BMS1,BMS2,TCU
 SG_ Charger_Out_Current : 16|32@1+ (0.1,0.0) [0.0|20.0] "A"  BMS1,BMS2,TCU
 SG_ Charger_Out_Voltage : 0|16@1+ (0.1,0.0) [0.0|60.0] "V"  BMS1,BMS2,TCU

BO_ 1408 Send_VCU_Cmd: 8 Vector__XXX
 SG_ Sim_Charger_Volt_Req : 48|10@1+ (0.1,0.0) [0.0|1.0] "" Vector__XXX
 SG_ Sim_BMS_Char_Curr_Req : 40|8@1+ (0.1,0.0) [0.0|1.0] "" Vector__XXX
 SG_ Discharge_Mode : 38|1@1+ (1,0) [0.0|1.0] "" Vector__XXX
 SG_ Direct_Enable : 37|1@1+ (1,0) [0.0|1.0] "" Vector__XXX
 SG_ Ovr_Temp_Enable : 36|1@1+ (1,0) [0.0|1.0] "" Vector__XXX
 SG_ Und_Temp_Enable : 35|1@1+ (1,0) [0.0|1.0] "" Vector__XXX
 SG_ Temp_Fault_Enable : 34|1@1+ (1,0) [0.0|1.0] "" Vector__XXX
 SG_ Sim_Charger_Current_Req_Flg : 33|1@1+ (1,0) [0.0|1.0] "" Vector__XXX
 SG_ Voltage_Fault_Enable : 32|1@1+ (1,0) [0.0|1.0] "" Vector__XXX
 SG_ Current_Sim_Value : 16|16@1+ (0.01,0.0) [0|0] "A" Vector__XXX
 SG_ Cell_Fault_OV : 15|1@1+ (1,0) [0.0|1.0] "" Vector__XXX
 SG_ Slm_Charger_Volt_Enable_Flag : 14|1@1+ (1,0) [0.0|1.0] "" Vector__XXX
 SG_ Cell_Fault_UV : 13|1@1+ (1,0) [0.0|1.0] "" Vector__XXX
 SG_ Simulation_Enable : 12|1@1+ (1,0) [0.0|1.0] "" Vector__XXX
 SG_ Current_Dir : 11|1@1+ (1,0) [0.0|1.0] "" Vector__XXX
 SG_ Vehicle_Mode_L3 : 9|2@1+ (1,0) [0.0|3.0] "" Vector__XXX
 SG_ Ign : 8|1@1+ (1,0) [0.0|1.0] "" Vector__XXX
 SG_ Vehicle_Mode_L2 : 6|2@1+ (1,0) [0.0|3.0] "" Vector__XXX
 SG_ BMS_WakUp_Req : 4|2@1+ (1,0) [0.0|1.0] "" Vector__XXX
 SG_ Diagnostic_Flg : 3|1@1+ (1,0) [0.0|1.0] "" Vector__XXX
 SG_ Charge_Connected : 2|1@1+ (1,0) [0.0|1.0] "" Vector__XXX
 SG_ VCU_Wakup_Req : 0|2@1+ (1,0) [0.0|2.0] "" Vector__XXX

CM_ SG_ 256 Unique_ID "Unique ID of the Master Battey pack";
CM_ SG_ 256 SoC "SoC of the Master battery pack";
CM_ SG_ 257 Cell_Voltage_4 "individual cell voltage";
CM_ SG_ 257 Cell_Voltage_3 "individual cell voltage";
CM_ SG_ 257 Cell_Voltage_2 "individual cell voltage";
CM_ SG_ 257 Cell_Voltage_1 "individual cell voltage";
CM_ SG_ 258 Cell_Voltage_8 "individual cell voltage";
CM_ SG_ 258 Cell_Voltage_7 "individual cell voltage";
CM_ SG_ 258 Cell_Voltage_6 "individual cell voltage";
CM_ SG_ 258 Cell_Voltage_5 "individual cell voltage";
CM_ SG_ 259 Cell_Voltage_12 "individual cell voltage";
CM_ SG_ 259 Cell_Voltage_11 "individual cell voltage";
CM_ SG_ 259 Cell_Voltage_10 "individual cell voltage";
CM_ SG_ 259 Cell_Voltage_9 "individual cell voltage";
CM_ SG_ 260 Cell_Voltage_16 "individual cell voltage";
CM_ SG_ 260 Cell_Voltage_15 "individual cell voltage";
CM_ SG_ 260 Cell_Voltage_14 "individual cell voltage";
CM_ SG_ 260 Cell_Voltage_13 "individual cell voltage";
CM_ SG_ 261 SinglePack_Connected "It will indicate how many packs connected in the vehcile";
CM_ SG_ 261 Min_Cell_Voltage "Minimum Voltage in 16 cells";
CM_ SG_ 261 Max_Cell_Voltage "Maximum voltage in 16 cells";
CM_ SG_ 262 PDU_Temperature_BMS "Temperature measured near the MOSFETs read by BMS";
CM_ SG_ 262 PDU_Temperature_AFE "PDU temperature read by AFE";
CM_ SG_ 263 Battery_Pack_Effective_Temp "Battery pack effective temperature (Tbatt)";
CM_ SG_ 263 Balancing_Temperature_AFE "Balancing temperature read by AFE";
CM_ SG_ 264 Battery_Pack_Temp_Sensor_2 "Measured Pack temperature from Sensor 2";
CM_ SG_ 264 Battery_Pack_Temp_Sensor_1 "Measured Pack temperature from Sensor 1";
CM_ SG_ 265 Battery_Pack_Temp_Sensor_4 "Measured Pack temperature from Sensor 4";
CM_ SG_ 265 Battery_Pack_Temp_Sensor_3 "Measured Pack temperature from Sensor 3";
CM_ SG_ 272 Cell16_Balancing_Status "1 for Cell balancing happening
0 for Cell balancing not happening";
CM_ SG_ 272 Cell15_Balancing_Status "1 for Cell balancing happening
0 for Cell balancing not happening";
CM_ SG_ 272 Cell14_Balancing_Status "1 for Cell balancing happening
0 for Cell balancing not happening";
CM_ SG_ 272 Cell13_Balancing_Status "1 for Cell balancing happening
0 for Cell balancing not happening";
CM_ SG_ 272 Cell12_Balancing_Status "1 for Cell balancing happening
0 for Cell balancing not happening";
CM_ SG_ 272 Cell11_Balancing_Status "1 for Cell balancing happening
0 for Cell balancing not happening";
CM_ SG_ 272 Cell10_Balancing_Status "1 for Cell balancing happening
0 for Cell balancing not happening";
CM_ SG_ 272 Cell9_Balancing_Status "1 for Cell balancing happening
0 for Cell balancing not happening";
CM_ SG_ 272 Cell8_Balancing_Status "1 for Cell balancing happening
0 for Cell balancing not happening";
CM_ SG_ 272 Cell7_Balancing_Status "1 for Cell balancing happening
0 for Cell balancing not happening";
CM_ SG_ 272 Cell6_Balancing_Status "1 for Cell balancing happening
0 for Cell balancing not happening";
CM_ SG_ 272 Cell5_Balancing_Status "1 for Cell balancing happening
0 for Cell balancing not happening";
CM_ SG_ 272 Cell4_Balancing_Status "1 for Cell balancing happening
0 for Cell balancing not happening";
CM_ SG_ 272 Cell3_Balancing_Status "1 for Cell balancing happening
0 for Cell balancing not happening";
CM_ SG_ 272 Cell2_Balancing_Status "1 for Cell balancing happening
0 for Cell balancing not happening";
CM_ SG_ 272 Cell1_Balancing_Status "1 for Cell balancing happening
0 for Cell balancing not happening";
CM_ SG_ 272 BMS_SlowChg_Status "If Attempt happens, Need to check whether it is Passed or Failed
0 for Failed
1 for Passed";
CM_ SG_ 272 BMS_SlowChg_Auth "BMS to Slow charge authentication";
CM_ SG_ 272 BMS_Out_Status "All BMS digital output status (ON or OFF) 0--> Off, 1--> On";
CM_ SG_ 272 BMS_IN_Supply_9V "All BMS digital input status (ON or OFF) 0--> Off, 1--> On";
CM_ SG_ 273 Regenerative_Current_Limit "Max amount of Current that Feedback in the battery which is generated by Regenerative Breaking System";
CM_ SG_ 273 Discharge_Current_Limit "Level of Charge Of Battery Relative to its Capacity";
CM_ SG_ 274 Battery_Pack_Voltage "Voltage of the Battery Pack";
CM_ SG_ 275 Time_To_Charge "Prediction time to complete 100% charge";
CM_ SG_ 275 Bus_Voltage "Measured voltage after MOSFETs (Bus voltage)";
CM_ SG_ 275 SoH "State of health (Indication of health of the pack)";
CM_ SG_ 275 SoC "State of charge (Indication of available energy in the pack)";
CM_ SG_ 276 KwHr_Accumulated "Accumalated energy of a cycle";
CM_ SG_ 276 AmpHr_Accumulated "Accumalated capacity of a cycle";
CM_ SG_ 276 Cycle_Number "Number of times pack is completely charged and discharged";
CM_ SG_ 276 Cell_Voltage_deviation "Difference between maximum and minimum cell voltages";
CM_ SG_ 277 Cell_4_Internal_Resistance "Calculated IR of cell 4";
CM_ SG_ 277 Cell_3_Internal_Resistance "Calculated IR of cell 3";
CM_ SG_ 277 Cell_2_Internal_Resistance "Calculated IR of cell 2";
CM_ SG_ 277 Cell_1_Internal_Resistance "Calculated IR of cell 1";
CM_ SG_ 278 Cell_8_Internal_Resistance "Calculated IR of cell 8";
CM_ SG_ 278 Cell_7_Internal_Resistance "Calculated IR of cell 7";
CM_ SG_ 278 Cell_6_Internal_Resistance "Calculated IR of cell 6";
CM_ SG_ 278 Cell_5_Internal_Resistance "Calculated IR of cell 5";
CM_ SG_ 279 Cell_12_Internal_Resistance "Calculated IR of cell 12";
CM_ SG_ 279 Cell_11_Internal_Resistance "Calculated IR of cell 11";
CM_ SG_ 279 Cell_10_Internal_Resistance "Calculated IR of cell 10";
CM_ SG_ 279 Cell_9_Internal_Resistance "Calculated IR of cell 9";
CM_ SG_ 280 Cell_16_Internal_Resistance "Calculated IR of cell 16";
CM_ SG_ 280 Cell_15_Internal_Resistance "Calculated IR of cell 15";
CM_ SG_ 280 Cell_14_Internal_Resistance "Calculated IR of cell 14";
CM_ SG_ 280 Cell_13_Internal_Resistance "Calculated IR of cell 13";
CM_ SG_ 281 Charge_Demand_Current "Only during charging";
CM_ SG_ 281 Charge_Demand_Voltage "Only during charging";
CM_ SG_ 281 BMS_Charge_Mode "Charging mode state";
CM_ SG_ 288 RTC_Date "Day, Month, Year";
CM_ SG_ 289 RTC_Time "RTC time (Hour, min, sec)";
CM_ SG_ 290 Contactor_State "Contactor States";
CM_ SG_ 290 BMS_Modes "BMS modes";
CM_ SG_ 291 Ther_RunAway_Alert "1 for Indication of Thermal Run Away Alert";
CM_ SG_ 291 Therm_RunAway_CutOFF "1 for Indication of Thermal Run Away CutOff";
CM_ SG_ 291 PDU_TempRise_Perm "1 for Indication of Permanent Temperature Rise In PDU";
CM_ SG_ 291 Batt_TempRise_Perm "1 for Indication of Permanent Temperature Rise in Battery";
CM_ SG_ 291 Dis_CutOff "1 for Indication of Discharge Cut Off";
CM_ SG_ 291 Charge_CutOff "1 for Indication of Charge Cut Off";
CM_ SG_ 291 Dis_OvrTemp_Err "1 for Indication of Discharge Over Temperature Error";
CM_ SG_ 291 Dis_OvrTemp_Warn "1 for Indication of Discharge Over Temperature Warning";
CM_ SG_ 291 Chg_OvrTemp_Warn "1 for Indication of Charge Over Temperature Warning";
CM_ SG_ 291 Chg_Und_Vol_Warn "1 for Indication of Charge Under Voltage Warning";
CM_ SG_ 291 Chg_Ovr_Vol_Perm "1 for Indication of Permanent Charge Over Voltage";
CM_ SG_ 291 Chg_Ovr_Vol_Err "1 for Indication of Charge Over Voltage Error";
CM_ SG_ 291 Chg_Ovr_Vol_Warn "1 for Indication of Charge Over Voltage Warning";
CM_ SG_ 291 PDU_Temp_Err "1 for Indication of PDU Temperature Error";
CM_ SG_ 291 Over_Temp_Perm "1 for Indication of Permanent Over Temperature";
CM_ SG_ 291 Short_Circuit_Perm "1 for Indication of Permanent Short Circuit";
CM_ SG_ 291 Short_Circuit_Err "1 for Indication of Short Circuit Error";
CM_ SG_ 291 Cell_Und_Voltage_Err "1 for Indication of Cell Under Voltage";
CM_ SG_ 291 Cell_Ovr_Voltage_Err "1 for Indication of Cell Over Voltage";
CM_ SG_ 291 Dis_Connection_Err "1 for Indication of DisConnection Error";
CM_ SG_ 291 Main_Connection_Err "1 for Indication of Main Connection Error";
CM_ SG_ 291 Precharge_Fail_Perm "1 for Indication of Precharge Fail Permanent";
CM_ SG_ 291 Precharge_Fail "1 for Indication of Precharge Fail";
CM_ SG_ 291 PreCharge_Err_Short "1 for Indication of Precharge Short";
CM_ SG_ 291 BMS_CutOff "1 for Indicaiton of BMS Cut Off mode";
CM_ SG_ 292 Cell_4_OCV "Estimated from measured cell voltage - cell4";
CM_ SG_ 292 Cell_3_OCV "Estimated from measured cell voltage - cell3";
CM_ SG_ 292 Cell_2_OCV "Estimated from measured cell voltage - cell2";
CM_ SG_ 292 Cell_1_OCV "Estimated from measured cell voltage - cell1";
CM_ SG_ 293 Cell_8_OCV "Estimated from measured cell voltage - cell8";
CM_ SG_ 293 Cell_7_OCV "Estimated from measured cell voltage - cell7";
CM_ SG_ 293 Cell_6_OCV "Estimated from measured cell voltage - cell6";
CM_ SG_ 293 Cell_5_OCV "Estimated from measured cell voltage - cell5";
CM_ SG_ 294 Cell_12_OCV "Estimated from measured cell voltage - cell12";
CM_ SG_ 294 Cell_11_OCV "Estimated from measured cell voltage - cell11";
CM_ SG_ 294 Cell_10_OCV "Estimated from measured cell voltage - cell10";
CM_ SG_ 294 Cell_9_OCV "Estimated from measured cell voltage - cell9";
CM_ SG_ 295 Cell_16_OCV "Estimated from measured cell voltage - cell16";
CM_ SG_ 295 Cell_15_OCV "Estimated from measured cell voltage - cell15";
CM_ SG_ 295 Cell_14_OCV "Estimated from measured cell voltage - cell14";
CM_ SG_ 295 Cell_13_OCV "Estimated from measured cell voltage - cell13";
CM_ SG_ 512 Unique_ID "Unique ID of the Master Battey pack";
CM_ SG_ 512 SoC "SoC of the Master battery pack";
CM_ SG_ 513 Cell_Voltage_4 "individual cell voltage";
CM_ SG_ 513 Cell_Voltage_3 "individual cell voltage";
CM_ SG_ 513 Cell_Voltage_2 "individual cell voltage";
CM_ SG_ 513 Cell_Voltage_1 "individual cell voltage";
CM_ SG_ 514 Cell_Voltage_8 "individual cell voltage";
CM_ SG_ 514 Cell_Voltage_7 "individual cell voltage";
CM_ SG_ 514 Cell_Voltage_6 "individual cell voltage";
CM_ SG_ 514 Cell_Voltage_5 "individual cell voltage";
CM_ SG_ 515 Cell_Voltage_12 "individual cell voltage";
CM_ SG_ 515 Cell_Voltage_11 "individual cell voltage";
CM_ SG_ 515 Cell_Voltage_10 "individual cell voltage";
CM_ SG_ 515 Cell_Voltage_9 "individual cell voltage";
CM_ SG_ 516 Cell_Voltage_16 "individual cell voltage";
CM_ SG_ 516 Cell_Voltage_15 "individual cell voltage";
CM_ SG_ 516 Cell_Voltage_14 "individual cell voltage";
CM_ SG_ 516 Cell_Voltage_13 "individual cell voltage";
CM_ SG_ 517 Min_Cell_Voltage "Minimum Voltage in 14 cells";
CM_ SG_ 517 Max_Cell_Voltage "Maximum voltage in 14 cells";
CM_ SG_ 518 PDU_Temperature_BMS "Temperature measured near the MOSFETs read by BMS";
CM_ SG_ 518 PDU_Temperature_AFE "PDU temperature read by AFE";
CM_ SG_ 519 Battery_Pack_Effective_Temp "Battery pack effective temperature (Tbatt)";
CM_ SG_ 519 Balancing_Temperature_AFE "Balancing temperature read by AFE";
CM_ SG_ 520 Battery_Pack_Temp_Sensor_2 "Measured Pack temperature from Sensor 2";
CM_ SG_ 520 Battery_Pack_Temp_Sensor_1 "Measured Pack temperature from Sensor 1";
CM_ SG_ 521 Battery_Pack_Temp_Sensor_4 "Measured Pack temperature from Sensor 4";
CM_ SG_ 521 Battery_Pack_Temp_Sensor_3 "Measured Pack temperature from Sensor 3";
CM_ SG_ 528 Cell16_Balancing_Status "1 for Cell balancing happening
0 for Cell balancing not happening";
CM_ SG_ 528 Cell15_Balancing_Status "1 for Cell balancing happening
0 for Cell balancing not happening";
CM_ SG_ 528 Cell14_Balancing_Status "1 for Cell balancing happening
0 for Cell balancing not happening";
CM_ SG_ 528 Cell13_Balancing_Status "1 for Cell balancing happening
0 for Cell balancing not happening";
CM_ SG_ 528 Cell12_Balancing_Status "1 for Cell balancing happening
0 for Cell balancing not happening";
CM_ SG_ 528 Cell11_Balancing_Status "1 for Cell balancing happening
0 for Cell balancing not happening";
CM_ SG_ 528 Cell10_Balancing_Status "1 for Cell balancing happening
0 for Cell balancing not happening";
CM_ SG_ 528 Cell9_Balancing_Status "1 for Cell balancing happening
0 for Cell balancing not happening";
CM_ SG_ 528 Cell8_Balancing_Status "1 for Cell balancing happening
0 for Cell balancing not happening";
CM_ SG_ 528 Cell7_Balancing_Status "1 for Cell balancing happening
0 for Cell balancing not happening";
CM_ SG_ 528 Cell6_Balancing_Status "1 for Cell balancing happening
0 for Cell balancing not happening";
CM_ SG_ 528 Cell5_Balancing_Status "1 for Cell balancing happening
0 for Cell balancing not happening";
CM_ SG_ 528 Cell4_Balancing_Status "1 for Cell balancing happening
0 for Cell balancing not happening";
CM_ SG_ 528 Cell3_Balancing_Status "1 for Cell balancing happening
0 for Cell balancing not happening";
CM_ SG_ 528 Cell2_Balancing_Status "1 for Cell balancing happening
0 for Cell balancing not happening";
CM_ SG_ 528 Cell1_Balancing_Status "1 for Cell balancing happening
0 for Cell balancing not happening";
CM_ SG_ 528 BMS_SlowChg_Status "If Attempt happens, Need to check whether it is Passed or Failed
0 for Failed
1 for Passed";
CM_ SG_ 528 BMS_SlowChg_Auth "BMS to Slow charge authentication";
CM_ SG_ 528 BMS_Out_Status "All BMS digital output status (ON or OFF) 0--> Off, 1--> On";
CM_ SG_ 528 BMS_IN_Supply_9V "All BMS digital input status (ON or OFF) 0--> Off, 1--> On";
CM_ SG_ 529 Regenerative_Current_Limit "Max amount of Current that Feedback in the battery which is generated by Regenerative Breaking System";
CM_ SG_ 529 Discharge_Current_Limit "Level of Charge Of Battery Relative to its Capacity";
CM_ SG_ 530 Battery_Pack_Voltage "Voltage of the Battery Pack";
CM_ SG_ 531 Time_To_Charge "Prediction time to complete 100% charge";
CM_ SG_ 531 Bus_Voltage "Measured voltage after MOSFETs (Bus voltage)";
CM_ SG_ 531 SoH "State of health (Indication of health of the pack)";
CM_ SG_ 531 SoC "State of charge (Indication of available energy in the pack)";
CM_ SG_ 532 KwHr_Accumulated "Accumalated energy of a cycle";
CM_ SG_ 532 AmpHr_Accumulated "Accumalated capacity of a cycle";
CM_ SG_ 532 Cycle_Number "Number of times pack is completely charged and discharged";
CM_ SG_ 532 Cell_Voltage_deviation "Difference between maximum and minimum cell voltages";
CM_ SG_ 533 Cell_4_Internal_Resistance "Calculated IR of cell 4";
CM_ SG_ 533 Cell_3_Internal_Resistance "Calculated IR of cell 3";
CM_ SG_ 533 Cell_2_Internal_Resistance "Calculated IR of cell 2";
CM_ SG_ 533 Cell_1_Internal_Resistance "Calculated IR of cell 1";
CM_ SG_ 534 Cell_8_Internal_Resistance "Calculated IR of cell 8";
CM_ SG_ 534 Cell_7_Internal_Resistance "Calculated IR of cell 7";
CM_ SG_ 534 Cell_6_Internal_Resistance "Calculated IR of cell 6";
CM_ SG_ 534 Cell_5_Internal_Resistance "Calculated IR of cell 5";
CM_ SG_ 535 Cell_12_Internal_Resistance "Calculated IR of cell 12";
CM_ SG_ 535 Cell_11_Internal_Resistance "Calculated IR of cell 11";
CM_ SG_ 535 Cell_10_Internal_Resistance "Calculated IR of cell 10";
CM_ SG_ 535 Cell_9_Internal_Resistance "Calculated IR of cell 9";
CM_ SG_ 536 Cell_16_Internal_Resistance "Calculated IR of cell 16";
CM_ SG_ 536 Cell_15_Internal_Resistance "Calculated IR of cell 15";
CM_ SG_ 536 Cell_14_Internal_Resistance "Calculated IR of cell 14";
CM_ SG_ 536 Cell_13_Internal_Resistance "Calculated IR of cell 13";
CM_ SG_ 537 Charge_Demand_Current "Only during charging";
CM_ SG_ 537 Charge_Demand_Voltage "Only during charging";
CM_ SG_ 537 BMS_Charge_Mode "Charging mode state";
CM_ SG_ 544 RTC_Date "Day, Month, Year";
CM_ SG_ 545 RTC_Time "RTC time (Hour, min, sec)";
CM_ SG_ 546 Contactor_State "Contactor States";
CM_ SG_ 546 BMS_Modes "BMS modes";
CM_ SG_ 547 Ther_RunAway_Alert "1 for Indication of Thermal Run Away Alert";
CM_ SG_ 547 Therm_RunAway_CutOFF "1 for Indication of Thermal Run Away CutOff";
CM_ SG_ 547 PDU_TempRise_Perm "1 for Indication of Permanent Temperature Rise In PDU";
CM_ SG_ 547 Batt_TempRise_Perm "1 for Indication of Permanent Temperature Rise in Battery";
CM_ SG_ 547 Dis_CutOff "1 for Indication of Discharge Cut Off";
CM_ SG_ 547 Charge_CutOff "1 for Indication of Charge Cut Off";
CM_ SG_ 547 Dis_OvrTemp_Err "1 for Indication of Discharge Over Temperature Error";
CM_ SG_ 547 Dis_OvrTemp_Warn "1 for Indication of Discharge Over Temperature Warning";
CM_ SG_ 547 Chg_OvrTemp_Warn "1 for Indication of Charge Over Temperature Warning";
CM_ SG_ 547 Chg_Und_Vol_Warn "1 for Indication of Charge Under Voltage Warning";
CM_ SG_ 547 Chg_Ovr_Vol_Perm "1 for Indication of Permanent Charge Over Voltage";
CM_ SG_ 547 Chg_Ovr_Vol_Err "1 for Indication of Charge Over Voltage Error";
CM_ SG_ 547 Chg_Ovr_Vol_Warn "1 for Indication of Charge Over Voltage Warning";
CM_ SG_ 547 PDU_Temp_Err "1 for Indication of PDU Temperature Error";
CM_ SG_ 547 Over_Temp_Perm "1 for Indication of Permanent Over Temperature";
CM_ SG_ 547 Short_Circuit_Perm "1 for Indication of Permanent Short Circuit";
CM_ SG_ 547 Short_Circuit_Err "1 for Indication of Short Circuit Error";
CM_ SG_ 547 Cell_Und_Voltage "1 for Indication of Cell Under Voltage";
CM_ SG_ 547 Cell_Ovr_Voltage "1 for Indication of Cell Over Voltage";
CM_ SG_ 547 Dis_Connection_Err "1 for Indication of DisConnection Error";
CM_ SG_ 547 Main_Connection_Err "1 for Indication of Main Connection Error";
CM_ SG_ 547 Precharge_Fail_Perm "1 for Indication of Precharge Fail Permanent";
CM_ SG_ 547 Precharge_Fail "1 for Indication of Precharge Fail";
CM_ SG_ 547 PreCharge_Err_Short "1 for Indication of Precharge Short";
CM_ SG_ 547 BMS_CutOff "1 for Indicaiton of BMS Cut Off mode";
CM_ SG_ 548 Cell_4_OCV "Estimated from measured cell voltage - cell4";
CM_ SG_ 548 Cell_3_OCV "Estimated from measured cell voltage - cell3";
CM_ SG_ 548 Cell_2_OCV "Estimated from measured cell voltage - cell2";
CM_ SG_ 548 Cell_1_OCV "Estimated from measured cell voltage - cell1";
CM_ SG_ 549 Cell_8_OCV "Estimated from measured cell voltage - cell8";
CM_ SG_ 549 Cell_7_OCV "Estimated from measured cell voltage - cell7";
CM_ SG_ 549 Cell_6_OCV "Estimated from measured cell voltage - cell6";
CM_ SG_ 549 Cell_5_OCV "Estimated from measured cell voltage - cell5";
CM_ SG_ 550 Cell_12_OCV "Estimated from measured cell voltage - cell12";
CM_ SG_ 550 Cell_11_OCV "Estimated from measured cell voltage - cell11";
CM_ SG_ 550 Cell_10_OCV "Estimated from measured cell voltage - cell10";
CM_ SG_ 550 Cell_9_OCV "Estimated from measured cell voltage - cell9";
CM_ SG_ 551 Cell_16_OCV "Estimated from measured cell voltage - cell16";
CM_ SG_ 551 Cell_15_OCV "Estimated from measured cell voltage - cell15";
CM_ SG_ 551 Cell_14_OCV "Estimated from measured cell voltage - cell14";
CM_ SG_ 551 Cell_13_OCV "Estimated from measured cell voltage - cell13";
BA_DEF_ BO_  "GenMsgCycleTime" INT 0 65535;
BA_DEF_DEF_  "GenMsgCycleTime" 0;
BA_ "GenMsgCycleTime" BO_ 256 100;
BA_ "GenMsgCycleTime" BO_ 257 100;
BA_ "GenMsgCycleTime" BO_ 258 100;
BA_ "GenMsgCycleTime" BO_ 259 100;
BA_ "GenMsgCycleTime" BO_ 260 100;
BA_ "GenMsgCycleTime" BO_ 261 100;
BA_ "GenMsgCycleTime" BO_ 262 100;
BA_ "GenMsgCycleTime" BO_ 263 100;
BA_ "GenMsgCycleTime" BO_ 264 100;
BA_ "GenMsgCycleTime" BO_ 265 100;
BA_ "GenMsgCycleTime" BO_ 272 100;
BA_ "GenMsgCycleTime" BO_ 273 100;
BA_ "GenMsgCycleTime" BO_ 274 100;
BA_ "GenMsgCycleTime" BO_ 275 100;
BA_ "GenMsgCycleTime" BO_ 276 100;
BA_ "GenMsgCycleTime" BO_ 277 100;
BA_ "GenMsgCycleTime" BO_ 278 100;
BA_ "GenMsgCycleTime" BO_ 279 100;
BA_ "GenMsgCycleTime" BO_ 280 100;
BA_ "GenMsgCycleTime" BO_ 281 100;
BA_ "GenMsgCycleTime" BO_ 288 100;
BA_ "GenMsgCycleTime" BO_ 289 100;
BA_ "GenMsgCycleTime" BO_ 290 10;
BA_ "GenMsgCycleTime" BO_ 291 200;
BA_ "GenMsgCycleTime" BO_ 292 100;
BA_ "GenMsgCycleTime" BO_ 293 100;
BA_ "GenMsgCycleTime" BO_ 294 100;
BA_ "GenMsgCycleTime" BO_ 295 100;
BA_ "GenMsgCycleTime" BO_ 512 100;
BA_ "GenMsgCycleTime" BO_ 513 100;
BA_ "GenMsgCycleTime" BO_ 514 100;
BA_ "GenMsgCycleTime" BO_ 515 100;
BA_ "GenMsgCycleTime" BO_ 516 100;
BA_ "GenMsgCycleTime" BO_ 517 100;
BA_ "GenMsgCycleTime" BO_ 518 100;
BA_ "GenMsgCycleTime" BO_ 519 100;
BA_ "GenMsgCycleTime" BO_ 520 100;
BA_ "GenMsgCycleTime" BO_ 521 100;
BA_ "GenMsgCycleTime" BO_ 528 100;
BA_ "GenMsgCycleTime" BO_ 529 100;
BA_ "GenMsgCycleTime" BO_ 530 100;
BA_ "GenMsgCycleTime" BO_ 531 100;
BA_ "GenMsgCycleTime" BO_ 532 100;
BA_ "GenMsgCycleTime" BO_ 533 100;
BA_ "GenMsgCycleTime" BO_ 534 100;
BA_ "GenMsgCycleTime" BO_ 535 100;
BA_ "GenMsgCycleTime" BO_ 536 100;
BA_ "GenMsgCycleTime" BO_ 537 100;
BA_ "GenMsgCycleTime" BO_ 544 100;
BA_ "GenMsgCycleTime" BO_ 545 100;
BA_ "GenMsgCycleTime" BO_ 546 10;
BA_ "GenMsgCycleTime" BO_ 547 200;
BA_ "GenMsgCycleTime" BO_ 548 100;
BA_ "GenMsgCycleTime" BO_ 549 100;
BA_ "GenMsgCycleTime" BO_ 550 100;
BA_ "GenMsgCycleTime" BO_ 551 100;
BA_ "GenMsgCycleTime" BO_ 768 100;
BA_ "GenMsgCycleTime" BO_ 769 100;
BA_ "GenMsgCycleTime" BO_ 770 100;
BA_ "GenMsgCycleTime" BO_ 771 100;
BA_ "GenMsgCycleTime" BO_ 1024 100;
BA_ "GenMsgCycleTime" BO_ 1408 100;
VAL_ 272 Cell16_Balancing_Status 0 "Not_Balancing" 1 "Balancing" ;
VAL_ 272 Cell15_Balancing_Status 0 "Not_Balancing" 1 "Balancing" ;
VAL_ 272 Cell14_Balancing_Status 0 "Not_Balancing" 1 "Balancing" ;
VAL_ 272 Cell13_Balancing_Status 0 "Not_Balancing" 1 "Balancing" ;
VAL_ 272 Cell12_Balancing_Status 0 "Not_Balancing" 1 "Balancing" ;
VAL_ 272 Cell11_Balancing_Status 0 "Not_Balancing" 1 "Balancing" ;
VAL_ 272 Cell10_Balancing_Status 0 "Not_Balancing" 1 "Balancing" ;
VAL_ 272 Cell9_Balancing_Status 0 "Not_Balancing" 1 "Balancing" ;
VAL_ 272 Cell8_Balancing_Status 0 "Not_Balancing" 1 "Balancing" ;
VAL_ 272 Cell7_Balancing_Status 0 "Not_Balancing" 1 "Balancing" ;
VAL_ 272 Cell6_Balancing_Status 0 "Not_Balancing" 1 "Balancing" ;
VAL_ 272 Cell5_Balancing_Status 0 "Not_Balancing" 1 "Balancing" ;
VAL_ 272 Cell4_Balancing_Status 0 "Not_Balancing" 1 "Balancing" ;
VAL_ 272 Cell3_Balancing_Status 0 "Not_Balancing" 1 "Balancing" ;
VAL_ 272 Cell2_Balancing_Status 0 "Not_Balancing" 1 "Balancing" ;
VAL_ 272 Cell1_Balancing_Status 0 "Not_Balancing" 1 "Balancing" ;
VAL_ 272 BMS_SlowChg_Status 0 "Fail" 1 "Pass" ;
VAL_ 272 BMS_SlowChg_Auth 0 "No_attempt" 1 "Attempt" ;
VAL_ 272 BMS_Out_3_3VEnable 0 "Disable" 1 "Enable" ;
VAL_ 272 BMS_Out_Overload_Clear 0 "Overload_Unclear" 1 "Overload_Clear" ;
VAL_ 272 BMS_Out_AFE_Reset 0 "AFE_NoReset" 1 "AFE_Reset" ;
VAL_ 272 BMS_Out_Precharge_FET_Enable 0 "Disable" 1 "Enable" ;
VAL_ 272 BMS_Out_Discharge_FET_Enable 0 "Disable" 1 "Enable" ;
VAL_ 272 BMS_Out_Charge_FET_Enable 0 "Disable" 1 "Enable" ;
VAL_ 272 BMS_Out_Gate_Driver_Enable 0 "Disable" 1 "Enable" ;
VAL_ 272 BMS_Out_5VEnable 0 "Disable" 1 "Enable" ;
VAL_ 272 BMS_Out_9VEnable 0 "Disable" 1 "Enable" ;
VAL_ 272 BMS_Out_12VEnable 0 "Disable" 1 "Enable" ;
VAL_ 272 BMS_Out_Status 0 "Disable" 1 "Enable" ;
VAL_ 272 BMS_IN_PlugSense 0 "Off_Improper" 1 "On_Proper" ;
VAL_ 272 BMS_IN_Discharge_Overcurrent 0 "Off_Improper" 1 "On_Proper" ;
VAL_ 272 BMS_IN_Charge_Overcurrent 0 "Off_Improper" 1 "On_Proper" ;
VAL_ 272 BMS_IN_AFE_Fault 0 "Off_Improper" 1 "On_Proper" ;
VAL_ 272 BMS_IN_Supply_12V 0 "Off_Improper" 1 "On_Proper" ;
VAL_ 272 BMS_IN_Supply_9V 0 "Off_Improper" 1 "On_Proper" ;
VAL_ 281 BMS_Charge_Mode 0 "Disabled" 1 "CC" 2 "CC_END" 3 "CV" 4 "Charge_Complete" ;
VAL_ 290 DisChg_Cont_Cmd 0 "Disconnected" 1 "Connected" ;
VAL_ 290 Chg_Cont_Cmd 0 "Disconnected" 1 "Connected" ;
VAL_ 290 Prechg_Cont_Cmd 0 "Disconnected" 1 "Connected" ;
VAL_ 290 Contactor_State 0 "Disconnected" 1 "PreCharge" 2 "PreChargeMain" 3 "Connected" 4 "Disconnect_Pending" ;
VAL_ 290 BMS_Modes 0 "INIT" 1 "Standby" 2 "Charge" 3 "Discharge" 4 "Fault" 5 "Sleep_Pending" 6 "Sleep" ;
VAL_ 291 Ther_RunAway_Alert 0 "No_Ther_RunAwy_Alrt" 1 "Ther_RunAwy_Alrt" ;
VAL_ 291 Therm_RunAway_CutOFF 0 "No_Ther_RunAwy_CutOff" 1 "Ther_RunAwy_CutOff" ;
VAL_ 291 PDU_TempRise_Perm 0 "No_PDU_TempRise_Perm" 1 "PDU_TempRise_Perm" ;
VAL_ 291 Batt_TempRise_Perm 0 "No_Batt_TempRise_Perm" 1 "Batt_TempRise_Perm" ;
VAL_ 291 Dis_CutOff 0 "No_Dis_CutOff" 1 "Dis_CutOff" ;
VAL_ 291 Charge_CutOff 0 "No_Charge_CutOff" 1 "Charge_CutOff" ;
VAL_ 291 Dis_OvrTemp_Err 0 "No_Dis_OvrTemp_Err" 1 "Dis_OvrTemp_Err" ;
VAL_ 291 Dis_OvrTemp_Warn 0 "No_Dis_OvrTemp_Warn" 1 "Dis_OvrTemp_Warn" ;
VAL_ 291 Chg_OvrTemp_Warn 0 "No_Chg_OvrTemp_Warn" 1 "Chg_OvrTemp_Warn" ;
VAL_ 291 Chg_Und_Vol_Warn 0 "No_Chg_UndVol_Warn" 1 "Chg_UndVol_Warn" ;
VAL_ 291 Chg_Ovr_Vol_Perm 0 "No_Chg_OvrVol_Perm" 1 "Chg_OvrVol_Perm" ;
VAL_ 291 Chg_Ovr_Vol_Err 0 "No_Chg_OvrVol_Err" 1 "Chg_OvrVol_Err" ;
VAL_ 291 Chg_Ovr_Vol_Warn 0 "No_Chg_OvrVol_Warn" 1 "Chg_OvrVol_Warn" ;
VAL_ 291 PDU_Temp_Err 0 "No_PDU_Temp_Err" 1 "PDU_Temp_Err" ;
VAL_ 291 Over_Temp_Perm 0 "No_Over_Temp_Perm" 1 "Over_Temp_Perm" ;
VAL_ 291 Short_Circuit_Perm 0 "No_Short_Circuit_Perm" 1 "Short_Circuit_Perm" ;
VAL_ 291 Short_Circuit_Err 0 "No_Short_Circuit" 1 "Short_Circuit" ;
VAL_ 291 Cell_Und_Voltage_Perm 0 "No_Cell_Und_Voltage_Perm" 1 "Cell_Und_Voltage_Perm" ;
VAL_ 291 Cell_Ovr_Voltage_Perm 0 "No_Cell_Ovr_Voltage_Perm" 1 "Cell_Ovr_Voltage_Perm" ;
VAL_ 291 Cell_Und_Voltage_Err 0 "No_Cell_Und_Volt" 1 "Cell_Und_Volt" ;
VAL_ 291 Cell_Ovr_Voltage_Err 0 "No_Cell_Ovr_Volt" 1 "Cell_Ovr_Volt" ;
VAL_ 291 Dis_Connection_Err 0 "No_Dis_Conn_Err" 1 "Dis_Conn_Err" ;
VAL_ 291 Main_Connection_Err 0 "No_Main_Conn_Err" 1 "Main_Conn_Err" ;
VAL_ 291 Precharge_Fail_Perm 0 "No_PreChg_Fail_Perm" 1 "Prechg_Fail_Perm" ;
VAL_ 291 Precharge_Fail 0 "No_PreChg_Fail" 1 "PreChg_Fail" ;
VAL_ 291 PreCharge_Err_Short 0 "No_PreChg_Short" 1 "PreChg_Short" ;
VAL_ 291 BMS_CutOff 0 "CutOff_Mode_Off" 1 "CutOff_Mode_On" ;
VAL_ 528 Cell16_Balancing_Status 0 "Not_Balancing" 1 "Balancing" ;
VAL_ 528 Cell15_Balancing_Status 0 "Not_Balancing" 1 "Balancing" ;
VAL_ 528 Cell14_Balancing_Status 0 "Not_Balancing" 1 "Balancing" ;
VAL_ 528 Cell13_Balancing_Status 0 "Not_Balancing" 1 "Balancing" ;
VAL_ 528 Cell12_Balancing_Status 0 "Not_Balancing" 1 "Balancing" ;
VAL_ 528 Cell11_Balancing_Status 0 "Not_Balancing" 1 "Balancing" ;
VAL_ 528 Cell10_Balancing_Status 0 "Not_Balancing" 1 "Balancing" ;
VAL_ 528 Cell9_Balancing_Status 0 "Not_Balancing" 1 "Balancing" ;
VAL_ 528 Cell8_Balancing_Status 0 "Not_Balancing" 1 "Balancing" ;
VAL_ 528 Cell7_Balancing_Status 0 "Not_Balancing" 1 "Balancing" ;
VAL_ 528 Cell6_Balancing_Status 0 "Not_Balancing" 1 "Balancing" ;
VAL_ 528 Cell5_Balancing_Status 0 "Not_Balancing" 1 "Balancing" ;
VAL_ 528 Cell4_Balancing_Status 0 "Not_Balancing" 1 "Balancing" ;
VAL_ 528 Cell3_Balancing_Status 0 "Not_Balancing" 1 "Balancing" ;
VAL_ 528 Cell2_Balancing_Status 0 "Not_Balancing" 1 "Balancing" ;
VAL_ 528 Cell1_Balancing_Status 0 "Not_Balancing" 1 "Balancing" ;
VAL_ 528 BMS_SlowChg_Status 0 "Fail" 1 "Pass" ;
VAL_ 528 BMS_SlowChg_Auth 0 "No_attempt" 1 "Attempt" ;
VAL_ 528 BMS_Out_3_3VEnable 0 "Disable" 1 "Enable" ;
VAL_ 528 BMS_Out_Overload_Clear 0 "Overload_Unclear" 1 "Overload_Clear" ;
VAL_ 528 BMS_Out_AFE_Reset 0 "AFE_NoReset" 1 "AFE_Reset" ;
VAL_ 528 BMS_Out_Precharge_FET_Enable 0 "Disable" 1 "Enable" ;
VAL_ 528 BMS_Out_Discharge_FET_Enable 0 "Disable" 1 "Enable" ;
VAL_ 528 BMS_Out_Charge_FET_Enable 0 "Disable" 1 "Enable" ;
VAL_ 528 BMS_Out_Gate_Driver_Enable 0 "Disable" 1 "Enable" ;
VAL_ 528 BMS_Out_5VEnable 0 "Disable" 1 "Enable" ;
VAL_ 528 BMS_Out_9VEnable 0 "Disable" 1 "Enable" ;
VAL_ 528 BMS_Out_12VEnable 0 "Disable" 1 "Enable" ;
VAL_ 528 BMS_Out_Status 0 "Disable" 1 "Enable" ;
VAL_ 528 BMS_IN_PlugSense 0 "Off_Improper" 1 "On_Proper" ;
VAL_ 528 BMS_IN_Discharge_Overcurrent 0 "Off_Improper" 1 "On_Proper" ;
VAL_ 528 BMS_IN_Charge_Overcurrent 0 "Off_Improper" 1 "On_Proper" ;
VAL_ 528 BMS_IN_AFE_Fault 0 "Off_Improper" 1 "On_Proper" ;
VAL_ 528 BMS_IN_Supply_12V 0 "Off_Improper" 1 "On_Proper" ;
VAL_ 528 BMS_IN_Supply_9V 0 "Off_Improper" 1 "On_Proper" ;
VAL_ 537 BMS_Charge_Mode 0 "Disabled" 1 "CC" 2 "CC_END" 3 "CV" 4 "Charge_Complete" ;
VAL_ 546 DisChg_Cont_Cmd 0 "Disconnected" 1 "Connected" ;
VAL_ 546 Chg_Cont_Cmd 0 "Disconnected" 1 "Connected" ;
VAL_ 546 Prechg_Cont_Cmd 0 "Disconnected" 1 "Connected" ;
VAL_ 546 Contactor_State 0 "Disconnected" 1 "PreCharge" 2 "PreChargeMain" 3 "Connected" 4 "Disconnect_Pending" ;
VAL_ 546 BMS_Modes 0 "INIT" 1 "Standby" 2 "Charge" 3 "Discharge" 4 "Fault" 5 "Sleep_Pending" 6 "Sleep" ;
VAL_ 547 Ther_RunAway_Alert 0 "No_Ther_RunAwy_Alrt" 1 "Ther_RunAwy_Alrt" ;
VAL_ 547 Therm_RunAway_CutOFF 0 "No_Ther_RunAwy_CutOff" 1 "Ther_RunAwy_CutOff" ;
VAL_ 547 PDU_TempRise_Perm 0 "No_PDU_TempRise_Perm" 1 "PDU_TempRise_Perm" ;
VAL_ 547 Batt_TempRise_Perm 0 "No_Batt_TempRise_Perm" 1 "Batt_TempRise_Perm" ;
VAL_ 547 Dis_CutOff 0 "No_Dis_CutOff" 1 "Dis_CutOff" ;
VAL_ 547 Charge_CutOff 0 "No_Charge_CutOff" 1 "Charge_CutOff" ;
VAL_ 547 Dis_OvrTemp_Err 0 "No_Dis_OvrTemp_Err" 1 "Dis_OvrTemp_Err" ;
VAL_ 547 Dis_OvrTemp_Warn 0 "No_Dis_OvrTemp_Warn" 1 "Dis_OvrTemp_Warn" ;
VAL_ 547 Chg_OvrTemp_Warn 0 "No_Chg_OvrTemp_Warn" 1 "Chg_OvrTemp_Warn" ;
VAL_ 547 Chg_Und_Vol_Warn 0 "No_Chg_UndVol_Warn" 1 "Chg_UndVol_Warn" ;
VAL_ 547 Chg_Ovr_Vol_Perm 0 "No_Chg_OvrVol_Perm" 1 "Chg_OvrVol_Perm" ;
VAL_ 547 Chg_Ovr_Vol_Err 0 "No_Chg_OvrVol_Err" 1 "Chg_OvrVol_Err" ;
VAL_ 547 Chg_Ovr_Vol_Warn 0 "No_Chg_OvrVol_Warn" 1 "Chg_OvrVol_Warn" ;
VAL_ 547 PDU_Temp_Err 0 "No_PDU_Temp_Err" 1 "PDU_Temp_Err" ;
VAL_ 547 Over_Temp_Perm 0 "No_Over_Temp_Perm" 1 "Over_Temp_Perm" ;
VAL_ 547 Short_Circuit_Perm 0 "No_Short_Circuit_Perm" 1 "Short_Circuit_Perm" ;
VAL_ 547 Short_Circuit_Err 0 "No_Short_Circuit" 1 "Short_Circuit" ;
VAL_ 547 Cell_Und_Voltage_Perm 0 "No_Cell_Und_Voltage_Perm" 1 "Cell_Und_Voltage_Perm" ;
VAL_ 547 Cell_Ovr_Voltage_Perm 0 "No_Cell_Ovr_Voltage_Perm" 1 "Cell_Ovr_Voltage_Perm" ;
VAL_ 547 Cell_Und_Voltage 0 "No_Cell_Und_Volt" 1 "Cell_Und_Volt" ;
VAL_ 547 Cell_Ovr_Voltage 0 "No_Cell_Ovr_Volt" 1 "Cell_Ovr_Volt" ;
VAL_ 547 Dis_Connection_Err 0 "No_Dis_Conn_Err" 1 "Dis_Conn_Err" ;
VAL_ 547 Main_Connection_Err 0 "No_Main_Conn_Err" 1 "Main_Conn_Err" ;
VAL_ 547 Precharge_Fail_Perm 0 "No_PreChg_Fail_Perm" 1 "Prechg_Fail_Perm" ;
VAL_ 547 Precharge_Fail 0 "No_PreChg_Fail" 1 "PreChg_Fail" ;
VAL_ 547 PreCharge_Err_Short 0 "No_PreChg_Short" 1 "PreChg_Short" ;
VAL_ 547 BMS_CutOff 0 "CutOff_Mode_Off" 1 "CutOff_Mode_On" ;
VAL_ 769 Regen_State 0 "Regen_Off" 1 "Regen_On" ;
VAL_ 769 BrakeSwitch_Status 0 "Brake_NotApplied" 1 "Brake_Applied" ;
VAL_ 769 SideStand_Status 0 "SideStand_DisEngaged" 1 "SideStand_Engaged" ;
VAL_ 769 Charge_CutOff 0 "No_Charge_CutOff" 1 "Charge_CutOff" ;
VAL_ 769 Drive_Modes 0 "Park" 1 "Mode_1" 2 "Mode_2" 3 "Mode_3" 4 "Reverse" ;
VAL_ 1024 Charger_CAN 0 "Normal" 1 "Communication_TimeOut" ;
VAL_ 1024 Charger_Start 0 "Normal" 1 "No_Load" ;
VAL_ 1024 Charger_Ready 0 "Normal" 1 "Initilization_Exception" ;
VAL_ 1024 Charger_Input 0 "Normal" 1 "Charger_Input_UnderVoltage" ;
VAL_ 1024 Charger_OverTemp 0 "Normal" 1 "Abnormal_Temperature" ;
VAL_ 1024 Charger_Hardware 0 "Normal" 1 "Hardware_Failure" ;
VAL_ 1408 Vehicle_Mode_L3 0 "NA" 1 "Normal" 2 "Sport" 3 "Hyper" ;
VAL_ 1408 Vehicle_Mode_L2 0 "VCU_SNA" 1 "VCU_Discharge" 2 "VCU_Charge" ;
VAL_ 1408 BMS_WakUp_Req 0 "No_WakeUp" 1 "CAN_WakeUp" 2 "RTC_WakeUp" ;
VAL_ 1408 VCU_Wakup_Req 0 "SNA" 1 "Req_WakUp" 2 "Req_Sleep" ;
